VERSION ""

NS_ :

BS_:
BU_: HVC MST DIST TEL MDI STR DRD MPPT MC MEMORATOR OBC
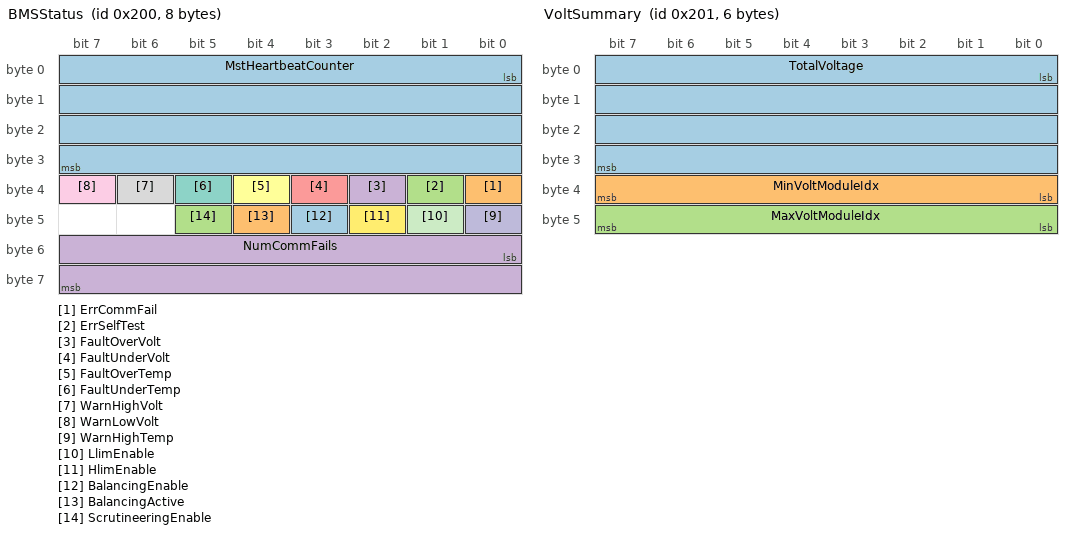
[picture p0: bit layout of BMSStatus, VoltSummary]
BO_ 512 BMSStatus: 8 MST
   SG_ MstHeartbeatCounter : 0|32@1+ (1,0) [0|4.29497e+09] "" HVC
   SG_ ErrCommFail : 32|1@1+ (1,0) [0|1] "" HVC
   SG_ ErrSelfTest : 33|1@1+ (1,0) [0|1] "" HVC
   SG_ FaultOverVolt : 34|1@1+ (1,0) [0|1] "" HVC
   SG_ FaultUnderVolt : 35|1@1+ (1,0) [0|1] "" HVC
   SG_ FaultOverTemp : 36|1@1+ (1,0) [0|1] "" HVC
   SG_ FaultUnderTemp : 37|1@1+ (1,0) [0|1] "" HVC
   SG_ WarnHighVolt : 38|1@1+ (1,0) [0|1] "" HVC
   SG_ WarnLowVolt : 39|1@1+ (1,0) [0|1] "" HVC
   SG_ WarnHighTemp : 40|1@1+ (1,0) [0|1] "" HVC
   SG_ LlimEnable : 41|1@1+ (1,0) [0|1] "" HVC
   SG_ HlimEnable : 42|1@1+ (1,0) [0|1] "" HVC
   SG_ BalancingEnable : 43|1@1+ (1,0) [0|1] "" HVC
   SG_ BalancingActive : 44|1@1+ (1,0) [0|1] "" HVC
   SG_ ScrutineeringEnable : 45|1@1+ (1,0) [0|1] "" HVC
   SG_ NumCommFails : 48|16@1+ (1,0) [0|65535] "" Vector__XXX

BO_ 513 VoltSummary: 6 MST
   SG_ TotalVoltage : 0|32@1+ (1,0) [0|4.29497e+09] "mV" HVC
   SG_ MinVoltModuleIdx : 32|8@1+ (1,0) [0|255] "" Vector__XXX
   SG_ MaxVoltModuleIdx : 40|8@1+ (1,0) [0|255] "" Vector__XXX

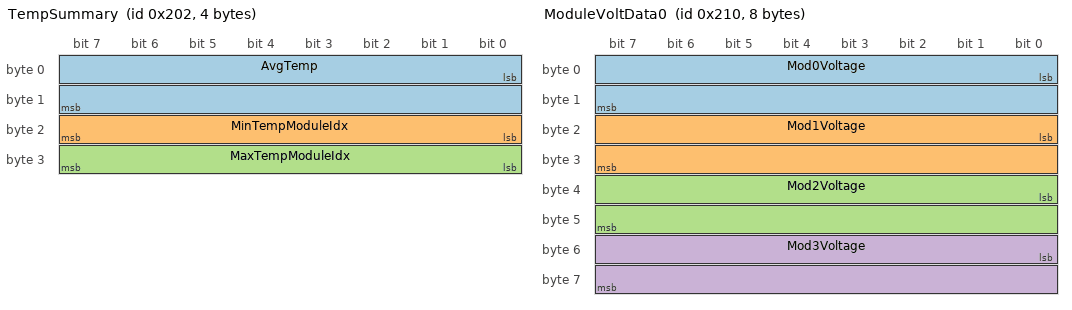
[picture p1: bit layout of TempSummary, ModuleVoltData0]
BO_ 514 TempSummary: 4 MST
   SG_ AvgTemp : 0|16@1- (1,0) [-32768|32767] "degC" Vector__XXX
   SG_ MinTempModuleIdx : 16|8@1+ (1,0) [0|255] "" Vector__XXX
   SG_ MaxTempModuleIdx : 24|8@1+ (1,0) [0|255] "" Vector__XXX

BO_ 515 BalanceData: 4 MST
   SG_ BalanceBitmap : 0|32@1+ (1,0) [0|4.29497e+09] "" Vector__XXX

BO_ 516 MSTCommitHash: 5 MST
   SG_ MSTCommitHash : 7|32@0+ (1,0) [0|4.29497e+09] "" Vector__XXX
   SG_ MSTCommitDirty : 32|1@1+ (1,0) [0|1] "" Vector__XXX

BO_ 528 ModuleVoltData0: 8 MST
   SG_ Mod0Voltage : 0|16@1+ (1,0) [0|65535] "mV" Vector__XXX
   SG_ Mod1Voltage : 16|16@1+ (1,0) [0|65535] "mV" Vector__XXX
   SG_ Mod2Voltage : 32|16@1+ (1,0) [0|65535] "mV" Vector__XXX
   SG_ Mod3Voltage : 48|16@1+ (1,0) [0|65535] "mV" Vector__XXX

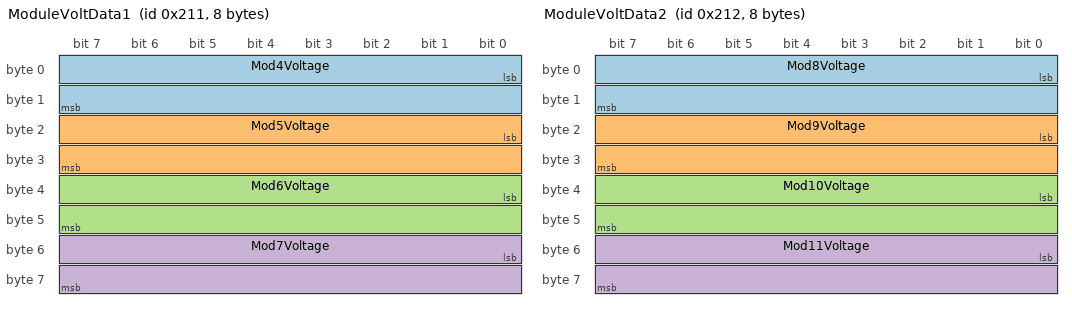
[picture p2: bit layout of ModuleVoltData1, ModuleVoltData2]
BO_ 529 ModuleVoltData1: 8 MST
   SG_ Mod4Voltage : 0|16@1+ (1,0) [0|65535] "mV" Vector__XXX
   SG_ Mod5Voltage : 16|16@1+ (1,0) [0|65535] "mV" Vector__XXX
   SG_ Mod6Voltage : 32|16@1+ (1,0) [0|65535] "mV" Vector__XXX
   SG_ Mod7Voltage : 48|16@1+ (1,0) [0|65535] "mV" Vector__XXX

BO_ 530 ModuleVoltData2: 8 MST
   SG_ Mod8Voltage : 0|16@1+ (1,0) [0|65535] "mV" Vector__XXX
   SG_ Mod9Voltage : 16|16@1+ (1,0) [0|65535] "mV" Vector__XXX
   SG_ Mod10Voltage : 32|16@1+ (1,0) [0|65535] "mV" Vector__XXX
   SG_ Mod11Voltage : 48|16@1+ (1,0) [0|65535] "mV" Vector__XXX

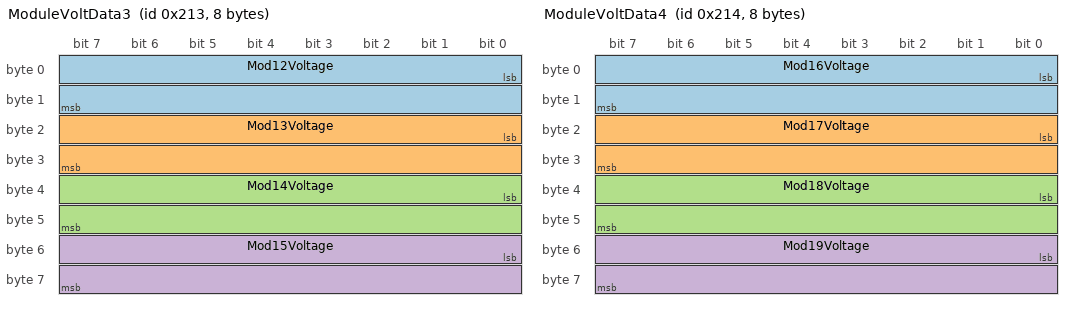
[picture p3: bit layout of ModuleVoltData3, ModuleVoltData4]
BO_ 531 ModuleVoltData3: 8 MST
   SG_ Mod12Voltage : 0|16@1+ (1,0) [0|65535] "mV" Vector__XXX
   SG_ Mod13Voltage : 16|16@1+ (1,0) [0|65535] "mV" Vector__XXX
   SG_ Mod14Voltage : 32|16@1+ (1,0) [0|65535] "mV" Vector__XXX
   SG_ Mod15Voltage : 48|16@1+ (1,0) [0|65535] "mV" Vector__XXX

BO_ 532 ModuleVoltData4: 8 MST
   SG_ Mod16Voltage : 0|16@1+ (1,0) [0|65535] "mV" Vector__XXX
   SG_ Mod17Voltage : 16|16@1+ (1,0) [0|65535] "mV" Vector__XXX
   SG_ Mod18Voltage : 32|16@1+ (1,0) [0|65535] "mV" Vector__XXX
   SG_ Mod19Voltage : 48|16@1+ (1,0) [0|65535] "mV" Vector__XXX

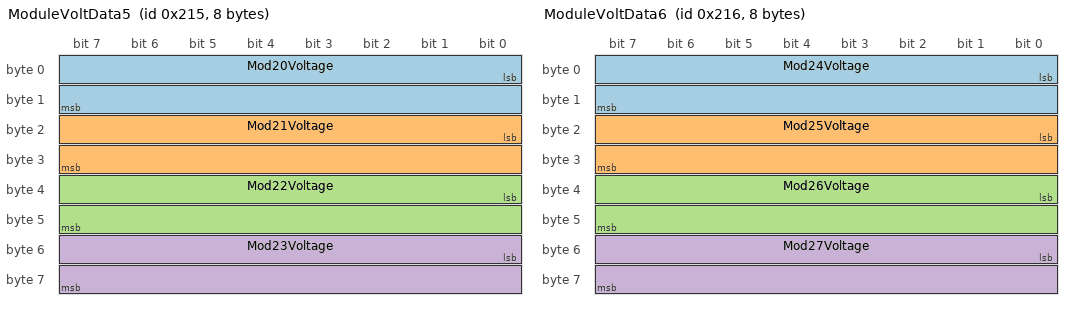
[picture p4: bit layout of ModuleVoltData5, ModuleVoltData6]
BO_ 533 ModuleVoltData5: 8 MST
   SG_ Mod20Voltage : 0|16@1+ (1,0) [0|65535] "mV" Vector__XXX
   SG_ Mod21Voltage : 16|16@1+ (1,0) [0|65535] "mV" Vector__XXX
   SG_ Mod22Voltage : 32|16@1+ (1,0) [0|65535] "mV" Vector__XXX
   SG_ Mod23Voltage : 48|16@1+ (1,0) [0|65535] "mV" Vector__XXX

BO_ 534 ModuleVoltData6: 8 MST
   SG_ Mod24Voltage : 0|16@1+ (1,0) [0|65535] "mV" Vector__XXX
   SG_ Mod25Voltage : 16|16@1+ (1,0) [0|65535] "mV" Vector__XXX
   SG_ Mod26Voltage : 32|16@1+ (1,0) [0|65535] "mV" Vector__XXX
   SG_ Mod27Voltage : 48|16@1+ (1,0) [0|65535] "mV" Vector__XXX

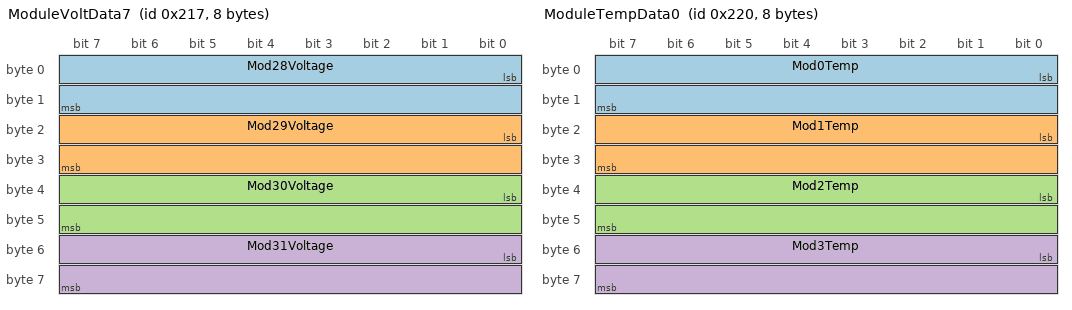
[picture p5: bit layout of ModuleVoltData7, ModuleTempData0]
BO_ 535 ModuleVoltData7: 8 MST
   SG_ Mod28Voltage : 0|16@1+ (1,0) [0|65535] "mV" Vector__XXX
   SG_ Mod29Voltage : 16|16@1+ (1,0) [0|65535] "mV" Vector__XXX
   SG_ Mod30Voltage : 32|16@1+ (1,0) [0|65535] "mV" Vector__XXX
   SG_ Mod31Voltage : 48|16@1+ (1,0) [0|65535] "mV" Vector__XXX

BO_ 544 ModuleTempData0: 8 MST
   SG_ Mod0Temp : 0|16@1- (1,0) [-32768|32767] "degC" Vector__XXX
   SG_ Mod1Temp : 16|16@1- (1,0) [-32768|32767] "degC" Vector__XXX
   SG_ Mod2Temp : 32|16@1- (1,0) [-32768|32767] "degC" Vector__XXX
   SG_ Mod3Temp : 48|16@1- (1,0) [-32768|32767] "degC" Vector__XXX

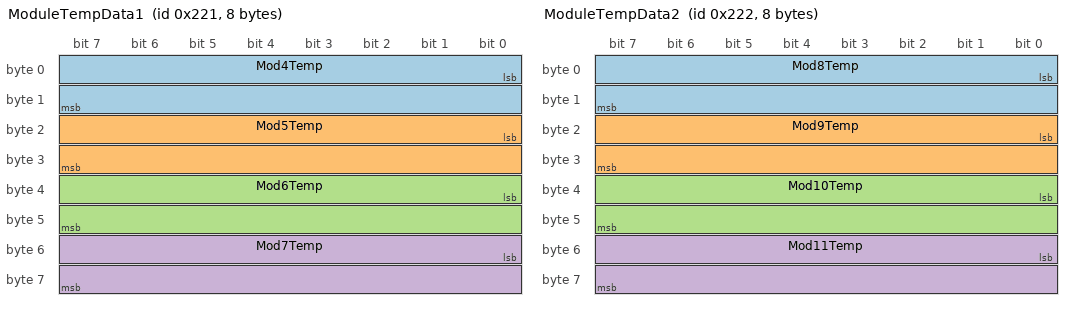
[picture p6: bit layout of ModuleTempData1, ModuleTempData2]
BO_ 545 ModuleTempData1: 8 MST
   SG_ Mod4Temp : 0|16@1- (1,0) [-32768|32767] "degC" Vector__XXX
   SG_ Mod5Temp : 16|16@1- (1,0) [-32768|32767] "degC" Vector__XXX
   SG_ Mod6Temp : 32|16@1- (1,0) [-32768|32767] "degC" Vector__XXX
   SG_ Mod7Temp : 48|16@1- (1,0) [-32768|32767] "degC" Vector__XXX

BO_ 546 ModuleTempData2: 8 MST
   SG_ Mod8Temp : 0|16@1- (1,0) [-32768|32767] "degC" Vector__XXX
   SG_ Mod9Temp : 16|16@1- (1,0) [-32768|32767] "degC" Vector__XXX
   SG_ Mod10Temp : 32|16@1- (1,0) [-32768|32767] "degC" Vector__XXX
   SG_ Mod11Temp : 48|16@1- (1,0) [-32768|32767] "degC" Vector__XXX

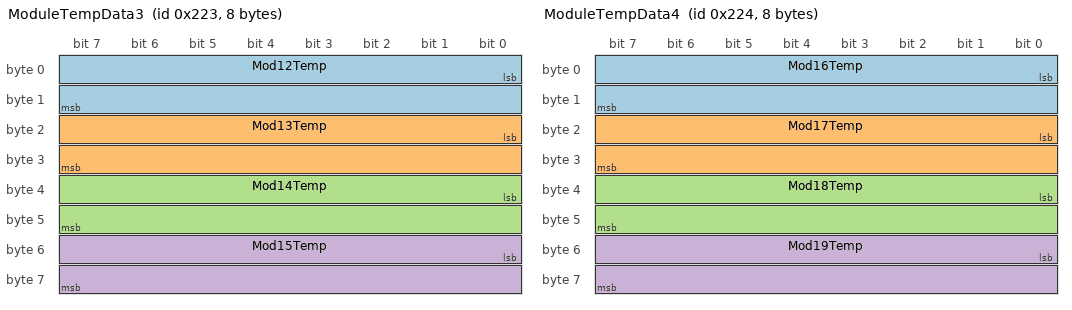
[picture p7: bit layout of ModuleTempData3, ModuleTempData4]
BO_ 547 ModuleTempData3: 8 MST
   SG_ Mod12Temp : 0|16@1- (1,0) [-32768|32767] "degC" Vector__XXX
   SG_ Mod13Temp : 16|16@1- (1,0) [-32768|32767] "degC" Vector__XXX
   SG_ Mod14Temp : 32|16@1- (1,0) [-32768|32767] "degC" Vector__XXX
   SG_ Mod15Temp : 48|16@1- (1,0) [-32768|32767] "degC" Vector__XXX

BO_ 548 ModuleTempData4: 8 MST
   SG_ Mod16Temp : 0|16@1- (1,0) [-32768|32767] "degC" Vector__XXX
   SG_ Mod17Temp : 16|16@1- (1,0) [-32768|32767] "degC" Vector__XXX
   SG_ Mod18Temp : 32|16@1- (1,0) [-32768|32767] "degC" Vector__XXX
   SG_ Mod19Temp : 48|16@1- (1,0) [-32768|32767] "degC" Vector__XXX

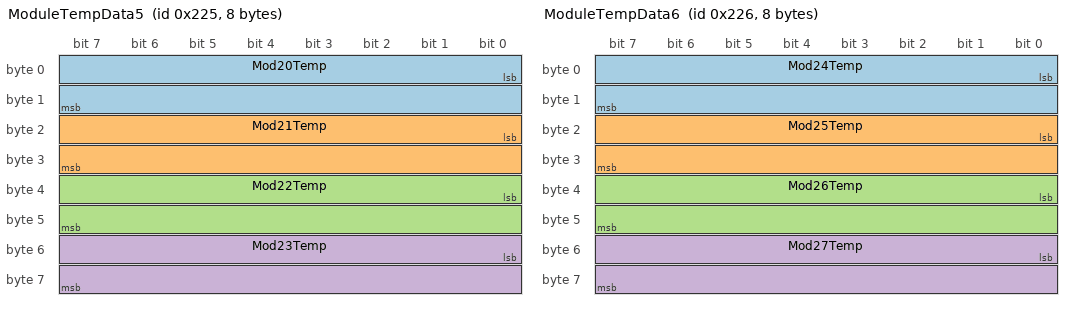
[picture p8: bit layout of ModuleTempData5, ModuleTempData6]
BO_ 549 ModuleTempData5: 8 MST
   SG_ Mod20Temp : 0|16@1- (1,0) [-32768|32767] "degC" Vector__XXX
   SG_ Mod21Temp : 16|16@1- (1,0) [-32768|32767] "degC" Vector__XXX
   SG_ Mod22Temp : 32|16@1- (1,0) [-32768|32767] "degC" Vector__XXX
   SG_ Mod23Temp : 48|16@1- (1,0) [-32768|32767] "degC" Vector__XXX

BO_ 550 ModuleTempData6: 8 MST
   SG_ Mod24Temp : 0|16@1- (1,0) [-32768|32767] "degC" Vector__XXX
   SG_ Mod25Temp : 16|16@1- (1,0) [-32768|32767] "degC" Vector__XXX
   SG_ Mod26Temp : 32|16@1- (1,0) [-32768|32767] "degC" Vector__XXX
   SG_ Mod27Temp : 48|16@1- (1,0) [-32768|32767] "degC" Vector__XXX

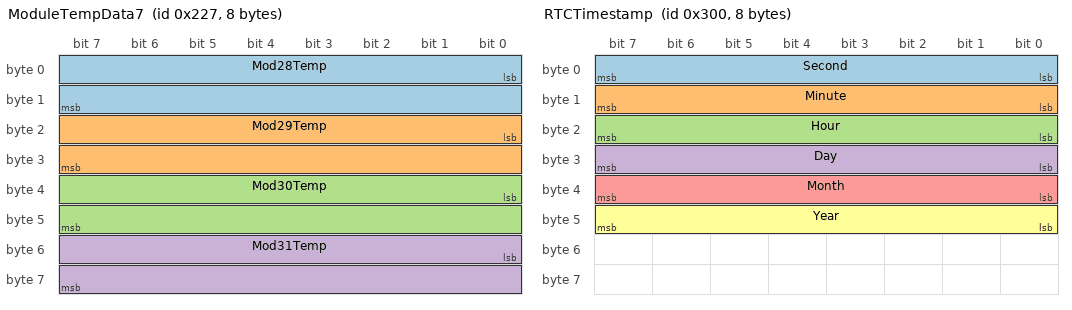
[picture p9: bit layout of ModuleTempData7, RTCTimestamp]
BO_ 551 ModuleTempData7: 8 MST
   SG_ Mod28Temp : 0|16@1- (1,0) [-32768|32767] "degC" Vector__XXX
   SG_ Mod29Temp : 16|16@1- (1,0) [-32768|32767] "degC" Vector__XXX
   SG_ Mod30Temp : 32|16@1- (1,0) [-32768|32767] "degC" Vector__XXX
   SG_ Mod31Temp : 48|16@1- (1,0) [-32768|32767] "degC" Vector__XXX

BO_ 560 ModuleWarnsAndFaults0: 8 MST
   SG_ Mod0WarnHighVolt : 0|1@1+ (1,0) [0|1] "" Vector__XXX
   SG_ Mod0WarnLowVolt : 1|1@1+ (1,0) [0|1] "" Vector__XXX
   SG_ Mod0WarnHighTemp : 2|1@1+ (1,0) [0|1] "" Vector__XXX
   SG_ Mod0FaultOverVolt : 4|1@1+ (1,0) [0|1] "" Vector__XXX
   SG_ Mod0FaultUnderVolt : 5|1@1+ (1,0) [0|1] "" Vector__XXX
   SG_ Mod0FaultOverTemp : 6|1@1+ (1,0) [0|1] "" Vector__XXX
   SG_ Mod0FaultUnderTemp : 7|1@1+ (1,0) [0|1] "" Vector__XXX
   SG_ Mod1WarnHighVolt : 8|1@1+ (1,0) [0|1] "" Vector__XXX
   SG_ Mod1WarnLowVolt : 9|1@1+ (1,0) [0|1] "" Vector__XXX
   SG_ Mod1WarnHighTemp : 10|1@1+ (1,0) [0|1] "" Vector__XXX
   SG_ Mod1FaultOverVolt : 12|1@1+ (1,0) [0|1] "" Vector__XXX
   SG_ Mod1FaultUnderVolt : 13|1@1+ (1,0) [0|1] "" Vector__XXX
   SG_ Mod1FaultOverTemp : 14|1@1+ (1,0) [0|1] "" Vector__XXX
   SG_ Mod1FaultUnderTemp : 15|1@1+ (1,0) [0|1] "" Vector__XXX
   SG_ Mod2WarnHighVolt : 16|1@1+ (1,0) [0|1] "" Vector__XXX
   SG_ Mod2WarnLowVolt : 17|1@1+ (1,0) [0|1] "" Vector__XXX
   SG_ Mod2WarnHighTemp : 18|1@1+ (1,0) [0|1] "" Vector__XXX
   SG_ Mod2FaultOverVolt : 20|1@1+ (1,0) [0|1] "" Vector__XXX
   SG_ Mod2FaultUnderVolt : 21|1@1+ (1,0) [0|1] "" Vector__XXX
   SG_ Mod2FaultOverTemp : 22|1@1+ (1,0) [0|1] "" Vector__XXX
   SG_ Mod2FaultUnderTemp : 23|1@1+ (1,0) [0|1] "" Vector__XXX
   SG_ Mod3WarnHighVolt : 24|1@1+ (1,0) [0|1] "" Vector__XXX
   SG_ Mod3WarnLowVolt : 25|1@1+ (1,0) [0|1] "" Vector__XXX
   SG_ Mod3WarnHighTemp : 26|1@1+ (1,0) [0|1] "" Vector__XXX
   SG_ Mod3FaultOverVolt : 28|1@1+ (1,0) [0|1] "" Vector__XXX
   SG_ Mod3FaultUnderVolt : 29|1@1+ (1,0) [0|1] "" Vector__XXX
   SG_ Mod3FaultOverTemp : 30|1@1+ (1,0) [0|1] "" Vector__XXX
   SG_ Mod3FaultUnderTemp : 31|1@1+ (1,0) [0|1] "" Vector__XXX
   SG_ Mod4WarnHighVolt : 32|1@1+ (1,0) [0|1] "" Vector__XXX
   SG_ Mod4WarnLowVolt : 33|1@1+ (1,0) [0|1] "" Vector__XXX
   SG_ Mod4WarnHighTemp : 34|1@1+ (1,0) [0|1] "" Vector__XXX
   SG_ Mod4FaultOverVolt : 36|1@1+ (1,0) [0|1] "" Vector__XXX
   SG_ Mod4FaultUnderVolt : 37|1@1+ (1,0) [0|1] "" Vector__XXX
   SG_ Mod4FaultOverTemp : 38|1@1+ (1,0) [0|1] "" Vector__XXX
   SG_ Mod4FaultUnderTemp : 39|1@1+ (1,0) [0|1] "" Vector__XXX
   SG_ Mod5WarnHighVolt : 40|1@1+ (1,0) [0|1] "" Vector__XXX
   SG_ Mod5WarnLowVolt : 41|1@1+ (1,0) [0|1] "" Vector__XXX
   SG_ Mod5WarnHighTemp : 42|1@1+ (1,0) [0|1] "" Vector__XXX
   SG_ Mod5FaultOverVolt : 44|1@1+ (1,0) [0|1] "" Vector__XXX
   SG_ Mod5FaultUnderVolt : 45|1@1+ (1,0) [0|1] "" Vector__XXX
   SG_ Mod5FaultOverTemp : 46|1@1+ (1,0) [0|1] "" Vector__XXX
   SG_ Mod5FaultUnderTemp : 47|1@1+ (1,0) [0|1] "" Vector__XXX
   SG_ Mod6WarnHighVolt : 48|1@1+ (1,0) [0|1] "" Vector__XXX
   SG_ Mod6WarnLowVolt : 49|1@1+ (1,0) [0|1] "" Vector__XXX
   SG_ Mod6WarnHighTemp : 50|1@1+ (1,0) [0|1] "" Vector__XXX
   SG_ Mod6FaultOverVolt : 52|1@1+ (1,0) [0|1] "" Vector__XXX
   SG_ Mod6FaultUnderVolt : 53|1@1+ (1,0) [0|1] "" Vector__XXX
   SG_ Mod6FaultOverTemp : 54|1@1+ (1,0) [0|1] "" Vector__XXX
   SG_ Mod6FaultUnderTemp : 55|1@1+ (1,0) [0|1] "" Vector__XXX
   SG_ Mod7WarnHighVolt : 56|1@1+ (1,0) [0|1] "" Vector__XXX
   SG_ Mod7WarnLowVolt : 57|1@1+ (1,0) [0|1] "" Vector__XXX
   SG_ Mod7WarnHighTemp : 58|1@1+ (1,0) [0|1] "" Vector__XXX
   SG_ Mod7FaultOverVolt : 60|1@1+ (1,0) [0|1] "" Vector__XXX
   SG_ Mod7FaultUnderVolt : 61|1@1+ (1,0) [0|1] "" Vector__XXX
   SG_ Mod7FaultOverTemp : 62|1@1+ (1,0) [0|1] "" Vector__XXX
   SG_ Mod7FaultUnderTemp : 63|1@1+ (1,0) [0|1] "" Vector__XXX

BO_ 561 ModuleWarnsAndFaults1: 8 MST
   SG_ Mod8WarnHighVolt : 0|1@1+ (1,0) [0|1] "" Vector__XXX
   SG_ Mod8WarnLowVolt : 1|1@1+ (1,0) [0|1] "" Vector__XXX
   SG_ Mod8WarnHighTemp : 2|1@1+ (1,0) [0|1] "" Vector__XXX
   SG_ Mod8FaultOverVolt : 4|1@1+ (1,0) [0|1] "" Vector__XXX
   SG_ Mod8FaultUnderVolt : 5|1@1+ (1,0) [0|1] "" Vector__XXX
   SG_ Mod8FaultOverTemp : 6|1@1+ (1,0) [0|1] "" Vector__XXX
   SG_ Mod8FaultUnderTemp : 7|1@1+ (1,0) [0|1] "" Vector__XXX
   SG_ Mod9WarnHighVolt : 8|1@1+ (1,0) [0|1] "" Vector__XXX
   SG_ Mod9WarnLowVolt : 9|1@1+ (1,0) [0|1] "" Vector__XXX
   SG_ Mod9WarnHighTemp : 10|1@1+ (1,0) [0|1] "" Vector__XXX
   SG_ Mod9FaultOverVolt : 12|1@1+ (1,0) [0|1] "" Vector__XXX
   SG_ Mod9FaultUnderVolt : 13|1@1+ (1,0) [0|1] "" Vector__XXX
   SG_ Mod9FaultOverTemp : 14|1@1+ (1,0) [0|1] "" Vector__XXX
   SG_ Mod9FaultUnderTemp : 15|1@1+ (1,0) [0|1] "" Vector__XXX
   SG_ Mod10WarnHighVolt : 16|1@1+ (1,0) [0|1] "" Vector__XXX
   SG_ Mod10WarnLowVolt : 17|1@1+ (1,0) [0|1] "" Vector__XXX
   SG_ Mod10WarnHighTemp : 18|1@1+ (1,0) [0|1] "" Vector__XXX
   SG_ Mod10FaultOverVolt : 20|1@1+ (1,0) [0|1] "" Vector__XXX
   SG_ Mod10FaultUnderVolt : 21|1@1+ (1,0) [0|1] "" Vector__XXX
   SG_ Mod10FaultOverTemp : 22|1@1+ (1,0) [0|1] "" Vector__XXX
   SG_ Mod10FaultUnderTemp : 23|1@1+ (1,0) [0|1] "" Vector__XXX
   SG_ Mod11WarnHighVolt : 24|1@1+ (1,0) [0|1] "" Vector__XXX
   SG_ Mod11WarnLowVolt : 25|1@1+ (1,0) [0|1] "" Vector__XXX
   SG_ Mod11WarnHighTemp : 26|1@1+ (1,0) [0|1] "" Vector__XXX
   SG_ Mod11FaultOverVolt : 28|1@1+ (1,0) [0|1] "" Vector__XXX
   SG_ Mod11FaultUnderVolt : 29|1@1+ (1,0) [0|1] "" Vector__XXX
   SG_ Mod11FaultOverTemp : 30|1@1+ (1,0) [0|1] "" Vector__XXX
   SG_ Mod11FaultUnderTemp : 31|1@1+ (1,0) [0|1] "" Vector__XXX
   SG_ Mod12WarnHighVolt : 32|1@1+ (1,0) [0|1] "" Vector__XXX
   SG_ Mod12WarnLowVolt : 33|1@1+ (1,0) [0|1] "" Vector__XXX
   SG_ Mod12WarnHighTemp : 34|1@1+ (1,0) [0|1] "" Vector__XXX
   SG_ Mod12FaultOverVolt : 36|1@1+ (1,0) [0|1] "" Vector__XXX
   SG_ Mod12FaultUnderVolt : 37|1@1+ (1,0) [0|1] "" Vector__XXX
   SG_ Mod12FaultOverTemp : 38|1@1+ (1,0) [0|1] "" Vector__XXX
   SG_ Mod12FaultUnderTemp : 39|1@1+ (1,0) [0|1] "" Vector__XXX
   SG_ Mod13WarnHighVolt : 40|1@1+ (1,0) [0|1] "" Vector__XXX
   SG_ Mod13WarnLowVolt : 41|1@1+ (1,0) [0|1] "" Vector__XXX
   SG_ Mod13WarnHighTemp : 42|1@1+ (1,0) [0|1] "" Vector__XXX
   SG_ Mod13FaultOverVolt : 44|1@1+ (1,0) [0|1] "" Vector__XXX
   SG_ Mod13FaultUnderVolt : 45|1@1+ (1,0) [0|1] "" Vector__XXX
   SG_ Mod13FaultOverTemp : 46|1@1+ (1,0) [0|1] "" Vector__XXX
   SG_ Mod13FaultUnderTemp : 47|1@1+ (1,0) [0|1] "" Vector__XXX
   SG_ Mod14WarnHighVolt : 48|1@1+ (1,0) [0|1] "" Vector__XXX
   SG_ Mod14WarnLowVolt : 49|1@1+ (1,0) [0|1] "" Vector__XXX
   SG_ Mod14WarnHighTemp : 50|1@1+ (1,0) [0|1] "" Vector__XXX
   SG_ Mod14FaultOverVolt : 52|1@1+ (1,0) [0|1] "" Vector__XXX
   SG_ Mod14FaultUnderVolt : 53|1@1+ (1,0) [0|1] "" Vector__XXX
   SG_ Mod14FaultOverTemp : 54|1@1+ (1,0) [0|1] "" Vector__XXX
   SG_ Mod14FaultUnderTemp : 55|1@1+ (1,0) [0|1] "" Vector__XXX
   SG_ Mod15WarnHighVolt : 56|1@1+ (1,0) [0|1] "" Vector__XXX
   SG_ Mod15WarnLowVolt : 57|1@1+ (1,0) [0|1] "" Vector__XXX
   SG_ Mod15WarnHighTemp : 58|1@1+ (1,0) [0|1] "" Vector__XXX
   SG_ Mod15FaultOverVolt : 60|1@1+ (1,0) [0|1] "" Vector__XXX
   SG_ Mod15FaultUnderVolt : 61|1@1+ (1,0) [0|1] "" Vector__XXX
   SG_ Mod15FaultOverTemp : 62|1@1+ (1,0) [0|1] "" Vector__XXX
   SG_ Mod15FaultUnderTemp : 63|1@1+ (1,0) [0|1] "" Vector__XXX

BO_ 562 ModuleWarnsAndFaults2: 8 MST
   SG_ Mod16WarnHighVolt : 0|1@1+ (1,0) [0|1] "" Vector__XXX
   SG_ Mod16WarnLowVolt : 1|1@1+ (1,0) [0|1] "" Vector__XXX
   SG_ Mod16WarnHighTemp : 2|1@1+ (1,0) [0|1] "" Vector__XXX
   SG_ Mod16FaultOverVolt : 4|1@1+ (1,0) [0|1] "" Vector__XXX
   SG_ Mod16FaultUnderVolt : 5|1@1+ (1,0) [0|1] "" Vector__XXX
   SG_ Mod16FaultOverTemp : 6|1@1+ (1,0) [0|1] "" Vector__XXX
   SG_ Mod16FaultUnderTemp : 7|1@1+ (1,0) [0|1] "" Vector__XXX
   SG_ Mod17WarnHighVolt : 8|1@1+ (1,0) [0|1] "" Vector__XXX
   SG_ Mod17WarnLowVolt : 9|1@1+ (1,0) [0|1] "" Vector__XXX
   SG_ Mod17WarnHighTemp : 10|1@1+ (1,0) [0|1] "" Vector__XXX
   SG_ Mod17FaultOverVolt : 12|1@1+ (1,0) [0|1] "" Vector__XXX
   SG_ Mod17FaultUnderVolt : 13|1@1+ (1,0) [0|1] "" Vector__XXX
   SG_ Mod17FaultOverTemp : 14|1@1+ (1,0) [0|1] "" Vector__XXX
   SG_ Mod17FaultUnderTemp : 15|1@1+ (1,0) [0|1] "" Vector__XXX
   SG_ Mod18WarnHighVolt : 16|1@1+ (1,0) [0|1] "" Vector__XXX
   SG_ Mod18WarnLowVolt : 17|1@1+ (1,0) [0|1] "" Vector__XXX
   SG_ Mod18WarnHighTemp : 18|1@1+ (1,0) [0|1] "" Vector__XXX
   SG_ Mod18FaultOverVolt : 20|1@1+ (1,0) [0|1] "" Vector__XXX
   SG_ Mod18FaultUnderVolt : 21|1@1+ (1,0) [0|1] "" Vector__XXX
   SG_ Mod18FaultOverTemp : 22|1@1+ (1,0) [0|1] "" Vector__XXX
   SG_ Mod18FaultUnderTemp : 23|1@1+ (1,0) [0|1] "" Vector__XXX
   SG_ Mod19WarnHighVolt : 24|1@1+ (1,0) [0|1] "" Vector__XXX
   SG_ Mod19WarnLowVolt : 25|1@1+ (1,0) [0|1] "" Vector__XXX
   SG_ Mod19WarnHighTemp : 26|1@1+ (1,0) [0|1] "" Vector__XXX
   SG_ Mod19FaultOverVolt : 28|1@1+ (1,0) [0|1] "" Vector__XXX
   SG_ Mod19FaultUnderVolt : 29|1@1+ (1,0) [0|1] "" Vector__XXX
   SG_ Mod19FaultOverTemp : 30|1@1+ (1,0) [0|1] "" Vector__XXX
   SG_ Mod19FaultUnderTemp : 31|1@1+ (1,0) [0|1] "" Vector__XXX
   SG_ Mod20WarnHighVolt : 32|1@1+ (1,0) [0|1] "" Vector__XXX
   SG_ Mod20WarnLowVolt : 33|1@1+ (1,0) [0|1] "" Vector__XXX
   SG_ Mod20WarnHighTemp : 34|1@1+ (1,0) [0|1] "" Vector__XXX
   SG_ Mod20FaultOverVolt : 36|1@1+ (1,0) [0|1] "" Vector__XXX
   SG_ Mod20FaultUnderVolt : 37|1@1+ (1,0) [0|1] "" Vector__XXX
   SG_ Mod20FaultOverTemp : 38|1@1+ (1,0) [0|1] "" Vector__XXX
   SG_ Mod20FaultUnderTemp : 39|1@1+ (1,0) [0|1] "" Vector__XXX
   SG_ Mod21WarnHighVolt : 40|1@1+ (1,0) [0|1] "" Vector__XXX
   SG_ Mod21WarnLowVolt : 41|1@1+ (1,0) [0|1] "" Vector__XXX
   SG_ Mod21WarnHighTemp : 42|1@1+ (1,0) [0|1] "" Vector__XXX
   SG_ Mod21FaultOverVolt : 44|1@1+ (1,0) [0|1] "" Vector__XXX
   SG_ Mod21FaultUnderVolt : 45|1@1+ (1,0) [0|1] "" Vector__XXX
   SG_ Mod21FaultOverTemp : 46|1@1+ (1,0) [0|1] "" Vector__XXX
   SG_ Mod21FaultUnderTemp : 47|1@1+ (1,0) [0|1] "" Vector__XXX
   SG_ Mod22WarnHighVolt : 48|1@1+ (1,0) [0|1] "" Vector__XXX
   SG_ Mod22WarnLowVolt : 49|1@1+ (1,0) [0|1] "" Vector__XXX
   SG_ Mod22WarnHighTemp : 50|1@1+ (1,0) [0|1] "" Vector__XXX
   SG_ Mod22FaultOverVolt : 52|1@1+ (1,0) [0|1] "" Vector__XXX
   SG_ Mod22FaultUnderVolt : 53|1@1+ (1,0) [0|1] "" Vector__XXX
   SG_ Mod22FaultOverTemp : 54|1@1+ (1,0) [0|1] "" Vector__XXX
   SG_ Mod22FaultUnderTemp : 55|1@1+ (1,0) [0|1] "" Vector__XXX
   SG_ Mod23WarnHighVolt : 56|1@1+ (1,0) [0|1] "" Vector__XXX
   SG_ Mod23WarnLowVolt : 57|1@1+ (1,0) [0|1] "" Vector__XXX
   SG_ Mod23WarnHighTemp : 58|1@1+ (1,0) [0|1] "" Vector__XXX
   SG_ Mod23FaultOverVolt : 60|1@1+ (1,0) [0|1] "" Vector__XXX
   SG_ Mod23FaultUnderVolt : 61|1@1+ (1,0) [0|1] "" Vector__XXX
   SG_ Mod23FaultOverTemp : 62|1@1+ (1,0) [0|1] "" Vector__XXX
   SG_ Mod23FaultUnderTemp : 63|1@1+ (1,0) [0|1] "" Vector__XXX

BO_ 563 ModuleWarnsAndFaults3: 8 MST
   SG_ Mod24WarnHighVolt : 0|1@1+ (1,0) [0|1] "" Vector__XXX
   SG_ Mod24WarnLowVolt : 1|1@1+ (1,0) [0|1] "" Vector__XXX
   SG_ Mod24WarnHighTemp : 2|1@1+ (1,0) [0|1] "" Vector__XXX
   SG_ Mod24FaultOverVolt : 4|1@1+ (1,0) [0|1] "" Vector__XXX
   SG_ Mod24FaultUnderVolt : 5|1@1+ (1,0) [0|1] "" Vector__XXX
   SG_ Mod24FaultOverTemp : 6|1@1+ (1,0) [0|1] "" Vector__XXX
   SG_ Mod24FaultUnderTemp : 7|1@1+ (1,0) [0|1] "" Vector__XXX
   SG_ Mod25WarnHighVolt : 8|1@1+ (1,0) [0|1] "" Vector__XXX
   SG_ Mod25WarnLowVolt : 9|1@1+ (1,0) [0|1] "" Vector__XXX
   SG_ Mod25WarnHighTemp : 10|1@1+ (1,0) [0|1] "" Vector__XXX
   SG_ Mod25FaultOverVolt : 12|1@1+ (1,0) [0|1] "" Vector__XXX
   SG_ Mod25FaultUnderVolt : 13|1@1+ (1,0) [0|1] "" Vector__XXX
   SG_ Mod25FaultOverTemp : 14|1@1+ (1,0) [0|1] "" Vector__XXX
   SG_ Mod25FaultUnderTemp : 15|1@1+ (1,0) [0|1] "" Vector__XXX
   SG_ Mod26WarnHighVolt : 16|1@1+ (1,0) [0|1] "" Vector__XXX
   SG_ Mod26WarnLowVolt : 17|1@1+ (1,0) [0|1] "" Vector__XXX
   SG_ Mod26WarnHighTemp : 18|1@1+ (1,0) [0|1] "" Vector__XXX
   SG_ Mod26FaultOverVolt : 20|1@1+ (1,0) [0|1] "" Vector__XXX
   SG_ Mod26FaultUnderVolt : 21|1@1+ (1,0) [0|1] "" Vector__XXX
   SG_ Mod26FaultOverTemp : 22|1@1+ (1,0) [0|1] "" Vector__XXX
   SG_ Mod26FaultUnderTemp : 23|1@1+ (1,0) [0|1] "" Vector__XXX
   SG_ Mod27WarnHighVolt : 24|1@1+ (1,0) [0|1] "" Vector__XXX
   SG_ Mod27WarnLowVolt : 25|1@1+ (1,0) [0|1] "" Vector__XXX
   SG_ Mod27WarnHighTemp : 26|1@1+ (1,0) [0|1] "" Vector__XXX
   SG_ Mod27FaultOverVolt : 28|1@1+ (1,0) [0|1] "" Vector__XXX
   SG_ Mod27FaultUnderVolt : 29|1@1+ (1,0) [0|1] "" Vector__XXX
   SG_ Mod27FaultOverTemp : 30|1@1+ (1,0) [0|1] "" Vector__XXX
   SG_ Mod27FaultUnderTemp : 31|1@1+ (1,0) [0|1] "" Vector__XXX
   SG_ Mod28WarnHighVolt : 32|1@1+ (1,0) [0|1] "" Vector__XXX
   SG_ Mod28WarnLowVolt : 33|1@1+ (1,0) [0|1] "" Vector__XXX
   SG_ Mod28WarnHighTemp : 34|1@1+ (1,0) [0|1] "" Vector__XXX
   SG_ Mod28FaultOverVolt : 36|1@1+ (1,0) [0|1] "" Vector__XXX
   SG_ Mod28FaultUnderVolt : 37|1@1+ (1,0) [0|1] "" Vector__XXX
   SG_ Mod28FaultOverTemp : 38|1@1+ (1,0) [0|1] "" Vector__XXX
   SG_ Mod28FaultUnderTemp : 39|1@1+ (1,0) [0|1] "" Vector__XXX
   SG_ Mod29WarnHighVolt : 40|1@1+ (1,0) [0|1] "" Vector__XXX
   SG_ Mod29WarnLowVolt : 41|1@1+ (1,0) [0|1] "" Vector__XXX
   SG_ Mod29WarnHighTemp : 42|1@1+ (1,0) [0|1] "" Vector__XXX
   SG_ Mod29FaultOverVolt : 44|1@1+ (1,0) [0|1] "" Vector__XXX
   SG_ Mod29FaultUnderVolt : 45|1@1+ (1,0) [0|1] "" Vector__XXX
   SG_ Mod29FaultOverTemp : 46|1@1+ (1,0) [0|1] "" Vector__XXX
   SG_ Mod29FaultUnderTemp : 47|1@1+ (1,0) [0|1] "" Vector__XXX
   SG_ Mod30WarnHighVolt : 48|1@1+ (1,0) [0|1] "" Vector__XXX
   SG_ Mod30WarnLowVolt : 49|1@1+ (1,0) [0|1] "" Vector__XXX
   SG_ Mod30WarnHighTemp : 50|1@1+ (1,0) [0|1] "" Vector__XXX
   SG_ Mod30FaultOverVolt : 52|1@1+ (1,0) [0|1] "" Vector__XXX
   SG_ Mod30FaultUnderVolt : 53|1@1+ (1,0) [0|1] "" Vector__XXX
   SG_ Mod30FaultOverTemp : 54|1@1+ (1,0) [0|1] "" Vector__XXX
   SG_ Mod30FaultUnderTemp : 55|1@1+ (1,0) [0|1] "" Vector__XXX
   SG_ Mod31WarnHighVolt : 56|1@1+ (1,0) [0|1] "" Vector__XXX
   SG_ Mod31WarnLowVolt : 57|1@1+ (1,0) [0|1] "" Vector__XXX
   SG_ Mod31WarnHighTemp : 58|1@1+ (1,0) [0|1] "" Vector__XXX
   SG_ Mod31FaultOverVolt : 60|1@1+ (1,0) [0|1] "" Vector__XXX
   SG_ Mod31FaultUnderVolt : 61|1@1+ (1,0) [0|1] "" Vector__XXX
   SG_ Mod31FaultOverTemp : 62|1@1+ (1,0) [0|1] "" Vector__XXX
   SG_ Mod31FaultUnderTemp : 63|1@1+ (1,0) [0|1] "" Vector__XXX

BO_ 768 RTCTimestamp: 8 MEMORATOR
   SG_ Second : 0|8@1+ (1,0) [0|59] "s" TEL
   SG_ Minute : 8|8@1+ (1,0) [0|59] "min" TEL
   SG_ Hour : 16|8@1+ (1,0) [0|23] "h" TEL
   SG_ Day : 24|8@1+ (1,0) [0.99999|31] "" TEL
   SG_ Month : 32|8@1+ (1,0) [0.99999|12] "" TEL
   SG_ Year : 40|8@1+ (1,0) [0|255] "" TEL

BO_ 800 HVCShuntCurrent: 4 HVC
   SG_ PackCurrent : 7|32@0- (1,0) [-2.14749e+09|2.14749e+09] "mA" Vector__XXX

BO_ 801 HvcFault: 3 HVC
   SG_ DcdcFault : 0|1@1+ (1,0) [0|1] "" DIST
   SG_ DistFaultFlag : 1|1@1+ (1,0) [0|1] "" DIST
   SG_ UndercurrentFault : 2|1@1+ (1,0) [0|1] "" DIST
   SG_ OvercurrentFault : 3|1@1+ (1,0) [0|1] "" DIST
   SG_ MstUnhealthyFault : 4|1@1+ (1,0) [0|1] "" DIST
   SG_ MasterboardFault : 5|1@1+ (1,0) [0|1] "" DIST
   SG_ ImdFault : 6|1@1+ (1,0) [0|1] "" DIST
   SG_ EstopFault : 7|1@1+ (1,0) [0|1] "" DIST
   SG_ OpenDischargeRelayTimeout : 8|1@1+ (1,0) [0|1] "" DIST
   SG_ HvConnectTimeout : 9|1@1+ (1,0) [0|1] "" DIST
   SG_ MstStatusCheckTimeout : 10|1@1+ (1,0) [0|1] "" DIST
   SG_ MstHandshakeTimeout : 11|1@1+ (1,0) [0|1] "" DIST
   SG_ TelStartupTimeout : 12|1@1+ (1,0) [0|1] "" DIST
   SG_ DcdcThermistorFault : 13|1@1+ (1,0) [0|1] "" DIST
   SG_ HVCWatchdogReset : 14|1@1+ (1,0) [0|1] "" DIST
   SG_ SuppFault : 15|1@1+ (1,0) [0|1] "" DIST
   SG_ DistHeartbeatTimeout : 18|1@1+ (1,0) [0|1] "" DIST
   SG_ MstHeartbeatTimeout : 19|1@1+ (1,0) [0|1] "" DIST
   SG_ TelHeartbeatTimeout : 20|1@1+ (1,0) [0|1] "" DIST
   SG_ LvPowerupTimeout : 21|1@1+ (1,0) [0|1] "" DIST
   SG_ MpptPrechargeTimeout : 22|1@1+ (1,0) [0|1] "" DIST
   SG_ MotorPrechargeTimeout : 23|1@1+ (1,0) [0|1] "" DIST

BO_ 802 HVCHeartbeat: 4 HVC
   SG_ HVCTimeSinceBootUp : 7|32@0+ (1,0) [0|4.29497e+09] "" Vector__XXX

BO_ 803 HVCLvPowerupSent: 1 HVC
   SG_ HVCLvPowerupSent : 0|8@1+ (1,0) [0|1] "" DIST

BO_ 804 HvcStatus: 1 HVC
   SG_ HVCState : 0|8@1+ (1,0) [0|14] "" Vector__XXX

BO_ 805 HvcLvCurrent: 2 HVC
   SG_ LvCurrent : 7|16@0- (1,0) [-32768|32767] "mA" Vector__XXX

BO_ 806 HvcDcdcTemp: 4 HVC
   SG_ DcdcTemperature : 7|32@0- (0.001,0) [-2.14749e+06|2.14749e+06] "degC" Vector__XXX

BO_ 807 HvcSuppVoltage: 4 HVC
   SG_ SuppVoltage : 7|32@0+ (1,0) [0|4.29497e+09] "mV" Vector__XXX

BO_ 808 HvcMcPrecharge: 4 HVC
   SG_ MotorPrechargeVoltage : 7|32@0- (1,0) [-2.14749e+09|2.14749e+09] "mV" Vector__XXX

BO_ 809 HvcMpptPrecharge: 4 HVC
   SG_ MpptPrechargeVoltage : 7|32@0- (1,0) [-2.14749e+09|2.14749e+09] "mV" Vector__XXX

BO_ 810 HVCCommitHash: 5 HVC
   SG_ HVCCommitHash : 7|32@0+ (1,0) [0|4.29497e+09] "" Vector__XXX
   SG_ HVCCommitDirty : 32|1@1+ (1,0) [0|1] "" Vector__XXX

BO_ 928 DISTHeartBeat: 4 DIST
   SG_ DISTHeartbeatCounter : 7|32@0+ (1,0) [0|4.29497e+09] "" HVC

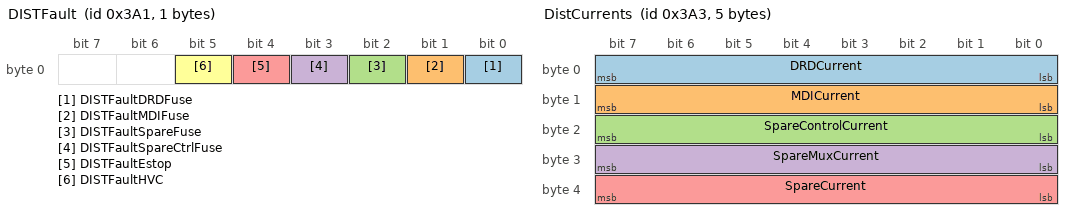
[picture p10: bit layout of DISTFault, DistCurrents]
BO_ 929 DISTFault: 1 DIST
   SG_ DISTFaultDRDFuse : 0|1@1+ (1,0) [0|1] "" HVC
   SG_ DISTFaultMDIFuse : 1|1@1+ (1,0) [0|1] "" HVC
   SG_ DISTFaultSpareFuse : 2|1@1+ (1,0) [0|1] "" HVC
   SG_ DISTFaultSpareCtrlFuse : 3|1@1+ (1,0) [0|1] "" HVC
   SG_ DISTFaultEstop : 4|1@1+ (1,0) [0|1] "" HVC
   SG_ DISTFaultHVC : 5|1@1+ (1,0) [0|1] "" HVC

BO_ 930 DISTLVOn: 1 DIST
   SG_ DISTLVOn : 0|8@1+ (1,0) [0|1] "" HVC

BO_ 931 DistCurrents: 5 DIST
   SG_ DRDCurrent : 0|8@1+ (5,0) [0|1275] "mA" Vector__XXX
   SG_ MDICurrent : 8|8@1+ (5,0) [0|1275] "mA" Vector__XXX
   SG_ SpareControlCurrent : 16|8@1+ (5,0) [0|1275] "mA" Vector__XXX
   SG_ SpareMuxCurrent : 24|8@1+ (5,0) [0|1275] "mA" Vector__XXX
   SG_ SpareCurrent : 32|8@1+ (5,0) [0|1275] "mA" Vector__XXX

BO_ 932 DISTBranchId: 1 DIST
   SG_ DISTBranchId : 0|8@1+ (1,0) [0|255] "" Vector__XXX

BO_ 933 DISTCommitHash: 5 DIST
   SG_ DISTCommitHash : 7|32@0+ (1,0) [0|4.29497e+09] "" Vector__XXX
   SG_ DISTCommitDirty : 32|1@1+ (1,0) [0|1] "" Vector__XXX

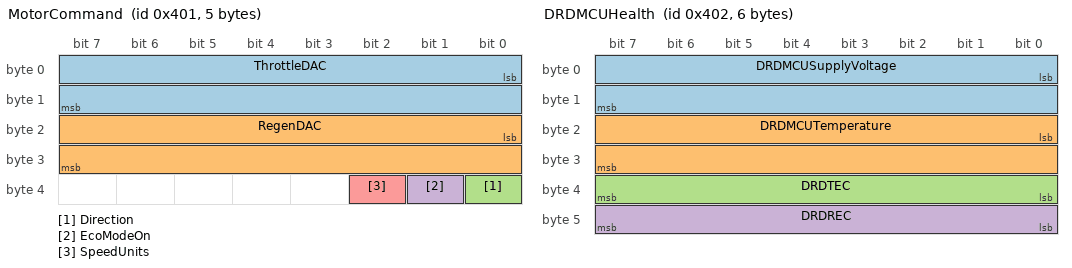
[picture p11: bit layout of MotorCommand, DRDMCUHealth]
BO_ 1025 MotorCommand: 5 DRD
   SG_ ThrottleDAC : 0|16@1+ (1,0) [0|1023] "" MDI
   SG_ RegenDAC : 16|16@1+ (1,0) [0|1023] "" MDI
   SG_ Direction : 32|1@1+ (1,0) [0|1] "" MDI
   SG_ EcoModeOn : 33|1@1+ (1,0) [0|1] "" MDI
   SG_ SpeedUnits : 34|1@1+ (1,0) [0|1] "" STR

BO_ 1026 DRDMCUHealth: 6 DRD
   SG_ DRDMCUSupplyVoltage : 0|16@1+ (1,0) [0|4000] "mV" Vector__XXX
   SG_ DRDMCUTemperature : 16|16@1- (1,0) [-40|125] "degC" Vector__XXX
   SG_ DRDTEC : 32|8@1+ (1,0) [0|255] "" Vector__XXX
   SG_ DRDREC : 40|8@1+ (1,0) [0|255] "" Vector__XXX

BO_ 1027 DRDDiagnostics: 8 DRD
   SG_ RawADC1 : 0|16@1+ (1,0) [0|65535] "" Vector__XXX
   SG_ RawADC2 : 16|16@1+ (1,0) [0|65535] "" Vector__XXX
   SG_ BrakePressed : 32|1@1+ (1,0) [0|1] "" Vector__XXX
   SG_ RegenEnabled : 33|1@1+ (1,0) [0|1] "" Vector__XXX
   SG_ ADCOutOfRange : 34|1@1+ (1,0) [0|1] "" Vector__XXX
   SG_ ADCMismatch : 35|1@1+ (1,0) [0|1] "" Vector__XXX
   SG_ DRDWatchdogReset : 36|1@1+ (1,0) [0|1] "" Vector__XXX
   SG_ MotorCommFault : 37|1@1+ (1,0) [0|1] "" Vector__XXX
   SG_ DRDMCUOverTemp : 38|1@1+ (1,0) [0|1] "" Vector__XXX
   SG_ DRDMCUUnderVoltage : 39|1@1+ (1,0) [0|1] "" Vector__XXX
   SG_ DriveState : 40|8@1+ (1,0) [0|255] "" Vector__XXX
   SG_ SpeedTimeout : 48|1@1+ (1,0) [0|1] "" Vector__XXX
   SG_ DriveStateTimeout : 49|1@1+ (1,0) [0|1] "" Vector__XXX
   SG_ SOCTimeout : 50|1@1+ (1,0) [0|1] "" Vector__XXX
   SG_ VoltageTimeout : 51|1@1+ (1,0) [0|1] "" Vector__XXX
   SG_ CurrentTimeout : 52|1@1+ (1,0) [0|1] "" Vector__XXX
   SG_ SOC : 56|8@1+ (1,0) [0|104] "%" Vector__XXX
   SG_ AccelTimeout : 53|1@1+ (1,0) [0|1] "" Vector__XXX

BO_ 1028 DRDTimeSinceBootup: 4 DRD
   SG_ DRDTimeSinceBootUp : 0|32@1+ (1,0) [0|4.29497e+09] "" Vector__XXX

BO_ 1029 DRDCommitHash: 5 DRD
   SG_ DRDCommitHash : 7|32@0+ (1,0) [0|4.29497e+09] "" Vector__XXX
   SG_ DRDCommitDirty : 32|1@1+ (1,0) [0|1] "" Vector__XXX

BO_ 1280 MDITimeSinceBootup: 4 MDI
   SG_ MDITimeSinceBootUp : 0|32@1+ (1,0) [0|4.29497e+09] "s" Vector__XXX

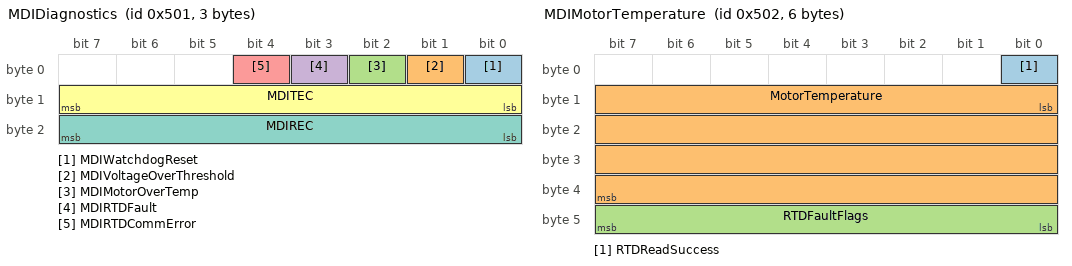
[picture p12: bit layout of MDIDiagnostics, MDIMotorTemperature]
BO_ 1281 MDIDiagnostics: 3 MDI
   SG_ MDIWatchdogReset : 0|1@1+ (1,0) [0|1] "" Vector__XXX
   SG_ MDIVoltageOverThreshold : 1|1@1+ (1,0) [0|1] "" Vector__XXX
   SG_ MDIMotorOverTemp : 2|1@1+ (1,0) [0|1] "" Vector__XXX
   SG_ MDIRTDFault : 3|1@1+ (1,0) [0|1] "" Vector__XXX
   SG_ MDIRTDCommError : 4|1@1+ (1,0) [0|1] "" Vector__XXX
   SG_ MDITEC : 8|8@1+ (1,0) [0|255] "" Vector__XXX
   SG_ MDIREC : 16|8@1+ (1,0) [0|255] "" Vector__XXX

BO_ 1282 MDIMotorTemperature: 6 MDI
   SG_ RTDReadSuccess : 0|1@1+ (1,0) [0|1] "" Vector__XXX
   SG_ MotorTemperature : 8|32@1- (1,0) [-100|300] "degC" Vector__XXX
   SG_ RTDFaultFlags : 40|8@1+ (1,0) [0|255] "" Vector__XXX

BO_ 1284 MDICommitHash: 5 MDI
   SG_ MDICommitHash : 7|32@0+ (1,0) [0|4.29497e+09] "" Vector__XXX
   SG_ MDICommitDirty : 32|1@1+ (1,0) [0|1] "" Vector__XXX

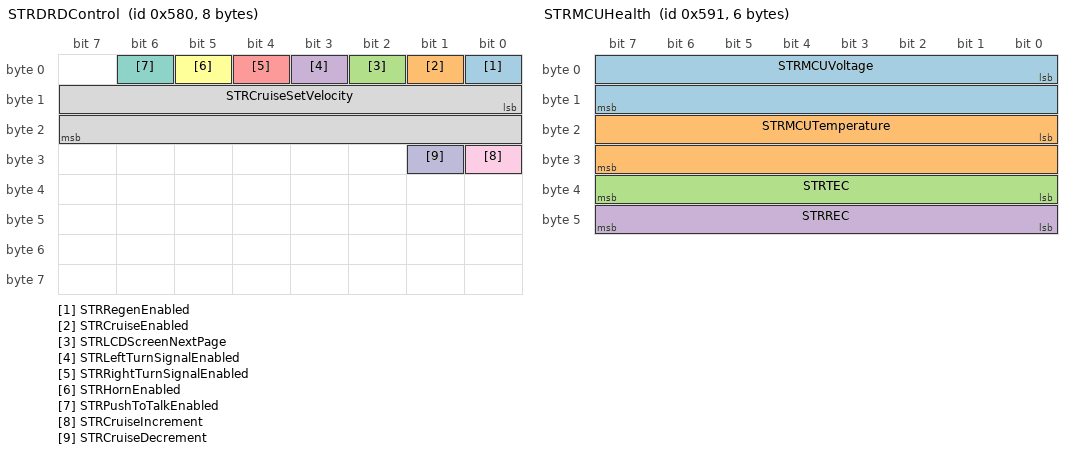
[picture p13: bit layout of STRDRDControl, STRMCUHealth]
BO_ 1408 STRDRDControl: 8 STR
   SG_ STRRegenEnabled : 0|1@1+ (1,0) [0|1] "" Vector__XXX
   SG_ STRCruiseEnabled : 1|1@1+ (1,0) [0|1] "" Vector__XXX
   SG_ STRLCDScreenNextPage : 2|1@1+ (1,0) [0|1] "" Vector__XXX
   SG_ STRLeftTurnSignalEnabled : 3|1@1+ (1,0) [0|1] "" Vector__XXX
   SG_ STRRightTurnSignalEnabled : 4|1@1+ (1,0) [0|1] "" Vector__XXX
   SG_ STRHornEnabled : 5|1@1+ (1,0) [0|1] "" Vector__XXX
   SG_ STRPushToTalkEnabled : 6|1@1+ (1,0) [0|1] "" Vector__XXX
   SG_ STRCruiseSetVelocity : 8|16@1+ (1,0) [0|65535] "km/h" Vector__XXX
   SG_ STRCruiseIncrement : 24|1@1+ (1,0) [0|1] "" Vector__XXX
   SG_ STRCruiseDecrement : 25|1@1+ (1,0) [0|1] "" Vector__XXX

BO_ 1409 STRTimeSinceBootup: 4 STR
   SG_ STRTimeSinceBootUp : 0|32@1+ (1,0) [0|4.29497e+09] "s" Vector__XXX

BO_ 1410 STRDiagnostics: 1 STR
   SG_ STRWatchdogReset : 0|1@1+ (1,0) [0|1] "" Vector__XXX

BO_ 1411 STRCommitHash: 5 STR
   SG_ STRCommitHash : 7|32@0+ (1,0) [0|4.29497e+09] "" Vector__XXX
   SG_ STRCommitDirty : 32|1@1+ (1,0) [0|1] "" Vector__XXX

BO_ 1425 STRMCUHealth: 6 STR
   SG_ STRMCUVoltage : 0|16@1+ (1,0) [0|65535] "mV" Vector__XXX
   SG_ STRMCUTemperature : 16|16@1- (1,0) [-40|125] "degC" Vector__XXX
   SG_ STRTEC : 32|8@1+ (1,0) [0|255] "" Vector__XXX
   SG_ STRREC : 40|8@1+ (1,0) [0|255] "" Vector__XXX

BO_ 1426 STRFlags: 1 STR
   SG_ STRMCUUnderVoltage : 0|1@1+ (1,0) [0|1] "" Vector__XXX
   SG_ STRMCUOverTemp : 1|1@1+ (1,0) [0|1] "" Vector__XXX

BO_ 1696 MPPTInputMeasurementsA: 8 MPPT
   SG_ InputVoltageA : 0|32@1- (1,0) [-3.4e+38|3.4e+38] "V" Vector__XXX
   SG_ InputCurrentA : 32|32@1- (1,0) [-3.4e+38|3.4e+38] "A" Vector__XXX

BO_ 1697 MPPTOutputMeasurementsA: 8 MPPT
   SG_ OutputVoltageA : 0|32@1- (1,0) [-3.4e+38|3.4e+38] "V" Vector__XXX
   SG_ OutputCurrentA : 32|32@1- (1,0) [-3.4e+38|3.4e+38] "A" Vector__XXX

BO_ 1698 MPPTTemperatureA: 8 MPPT
   SG_ MosfetTemperatureA : 0|32@1- (1,0) [-40|150] "degC" Vector__XXX
   SG_ ControllerTemperatureA : 32|32@1- (1,0) [-40|150] "degC" DRD

BO_ 1699 MPPTAuxiliaryPowerSupplyA: 8 MPPT
   SG_ Aux12VA : 0|32@1- (1,0) [0|20] "V" Vector__XXX
   SG_ Aux3VA : 32|32@1- (1,0) [0|5] "V" Vector__XXX

BO_ 1700 MPPTLimitsA: 8 MPPT
   SG_ MaxOutputVoltageLimitA : 0|32@1- (1,0) [-3.4e+38|3.4e+38] "V" Vector__XXX
   SG_ MaxInputCurrentLimitA : 32|32@1- (1,0) [-3.4e+38|3.4e+38] "A" Vector__XXX

BO_ 1701 MPPTStatusA: 8 MPPT
   SG_ CANRXErrorCounterA : 0|8@1+ (1,0) [0|255] "" Vector__XXX
   SG_ CANTXErrorCounterA : 8|8@1+ (1,0) [0|255] "" Vector__XXX
   SG_ CANTXOverflowCounterA : 16|8@1+ (1,0) [0|255] "" Vector__XXX
   SG_ HWOvervoltageA : 24|1@1+ (1,0) [0|1] "" Vector__XXX
   SG_ HWOvercurrentA : 25|1@1+ (1,0) [0|1] "" Vector__XXX
   SG_ Reserved1A : 26|1@1+ (1,0) [0|1] "" Vector__XXX
   SG_ Undervoltage12VA : 27|1@1+ (1,0) [0|1] "" Vector__XXX
   SG_ BatteryFullA : 28|1@1+ (1,0) [0|1] "" Vector__XXX
   SG_ BatteryLowA : 29|1@1+ (1,0) [0|1] "" Vector__XXX
   SG_ MosfetOverheatA : 30|1@1+ (1,0) [0|1] "" Vector__XXX
   SG_ LowArrayPowerA : 31|1@1+ (1,0) [0|1] "" Vector__XXX
   SG_ GlobalMPPTA : 32|1@1+ (1,0) [0|1] "" Vector__XXX
   SG_ LocalMPPTA : 33|1@1+ (1,0) [0|1] "" Vector__XXX
   SG_ DutyCycleMaxA : 34|1@1+ (1,0) [0|1] "" Vector__XXX
   SG_ DutyCycleMinA : 35|1@1+ (1,0) [0|1] "" Vector__XXX
   SG_ MosfetTempFaultA : 36|1@1+ (1,0) [0|1] "" Vector__XXX
   SG_ OutputVoltageMaxA : 37|1@1+ (1,0) [0|1] "" Vector__XXX
   SG_ InputCurrentMaxA : 38|1@1+ (1,0) [0|1] "" Vector__XXX
   SG_ InputCurrentMinA : 39|1@1+ (1,0) [0|1] "" Vector__XXX
   SG_ ModeA : 40|8@1+ (1,0) [0|1] "" Vector__XXX
   SG_ Reserved2A : 48|8@1+ (1,0) [0|255] "" Vector__XXX
   SG_ TestCounterA : 56|8@1+ (1,0) [0|255] "" Vector__XXX

BO_ 1702 MPPTPowerConnectorA: 8 MPPT
   SG_ OutputVoltageBattSideA : 0|32@1- (1,0) [-3.4e+38|3.4e+38] "V" Vector__XXX
   SG_ ConnectorTemperatureA : 32|32@1- (1,0) [-40|150] "degC" Vector__XXX

BO_ 1704 MPPTModeCommandA: 1 Vector__XXX
   SG_ ModeCmdA : 0|8@1+ (1,0) [0|1] "" Vector__XXX

BO_ 1706 MPPTMaxOutputVoltageCommandA: 4 Vector__XXX
   SG_ MaxOutputVoltageCmdA : 0|32@1- (1,0) [-3.4e+38|3.4e+38] "V" Vector__XXX

BO_ 1707 MPPTMaxOutputCurrentCommandA: 4 Vector__XXX
   SG_ MaxOutputCurrentCmdA : 0|32@1- (1,0) [-3.4e+38|3.4e+38] "A" Vector__XXX

BO_ 1712 MPPTInputMeasurementsB: 8 MPPT
   SG_ InputVoltageB : 0|32@1- (1,0) [-3.4e+38|3.4e+38] "V" Vector__XXX
   SG_ InputCurrentB : 32|32@1- (1,0) [-3.4e+38|3.4e+38] "A" Vector__XXX

BO_ 1713 MPPTOutputMeasurementsB: 8 MPPT
   SG_ OutputVoltageB : 0|32@1- (1,0) [-3.4e+38|3.4e+38] "V" Vector__XXX
   SG_ OutputCurrentB : 32|32@1- (1,0) [-3.4e+38|3.4e+38] "A" Vector__XXX

BO_ 1714 MPPTTemperatureB: 8 MPPT
   SG_ MosfetTemperatureB : 0|32@1- (1,0) [-40|150] "degC" Vector__XXX
   SG_ ControllerTemperatureB : 32|32@1- (1,0) [-40|150] "degC" DRD

BO_ 1715 MPPTAuxiliaryPowerSupplyB: 8 MPPT
   SG_ Aux12VB : 0|32@1- (1,0) [0|20] "V" Vector__XXX
   SG_ Aux3VB : 32|32@1- (1,0) [0|5] "V" Vector__XXX

BO_ 1716 MPPTLimitsB: 8 MPPT
   SG_ MaxOutputVoltageLimitB : 0|32@1- (1,0) [-3.4e+38|3.4e+38] "V" Vector__XXX
   SG_ MaxInputCurrentLimitB : 32|32@1- (1,0) [-3.4e+38|3.4e+38] "A" Vector__XXX

BO_ 1717 MPPTStatusB: 8 MPPT
   SG_ CANRXErrorCounterB : 0|8@1+ (1,0) [0|255] "" Vector__XXX
   SG_ CANTXErrorCounterB : 8|8@1+ (1,0) [0|255] "" Vector__XXX
   SG_ CANTXOverflowCounterB : 16|8@1+ (1,0) [0|255] "" Vector__XXX
   SG_ HWOvervoltageB : 24|1@1+ (1,0) [0|1] "" Vector__XXX
   SG_ HWOvercurrentB : 25|1@1+ (1,0) [0|1] "" Vector__XXX
   SG_ Reserved1B : 26|1@1+ (1,0) [0|1] "" Vector__XXX
   SG_ Undervoltage12VB : 27|1@1+ (1,0) [0|1] "" Vector__XXX
   SG_ BatteryFullB : 28|1@1+ (1,0) [0|1] "" Vector__XXX
   SG_ BatteryLowB : 29|1@1+ (1,0) [0|1] "" Vector__XXX
   SG_ MosfetOverheatB : 30|1@1+ (1,0) [0|1] "" Vector__XXX
   SG_ LowArrayPowerB : 31|1@1+ (1,0) [0|1] "" Vector__XXX
   SG_ GlobalMPPTB : 32|1@1+ (1,0) [0|1] "" Vector__XXX
   SG_ LocalMPPTB : 33|1@1+ (1,0) [0|1] "" Vector__XXX
   SG_ DutyCycleMaxB : 34|1@1+ (1,0) [0|1] "" Vector__XXX
   SG_ DutyCycleMinB : 35|1@1+ (1,0) [0|1] "" Vector__XXX
   SG_ MosfetTempFaultB : 36|1@1+ (1,0) [0|1] "" Vector__XXX
   SG_ OutputVoltageMaxB : 37|1@1+ (1,0) [0|1] "" Vector__XXX
   SG_ InputCurrentMaxB : 38|1@1+ (1,0) [0|1] "" Vector__XXX
   SG_ InputCurrentMinB : 39|1@1+ (1,0) [0|1] "" Vector__XXX
   SG_ ModeB : 40|8@1+ (1,0) [0|1] "" Vector__XXX
   SG_ Reserved2B : 48|8@1+ (1,0) [0|255] "" Vector__XXX
   SG_ TestCounterB : 56|8@1+ (1,0) [0|255] "" Vector__XXX

BO_ 1718 MPPTPowerConnectorB: 8 MPPT
   SG_ OutputVoltageBattSideB : 0|32@1- (1,0) [-3.4e+38|3.4e+38] "V" Vector__XXX
   SG_ ConnectorTemperatureB : 32|32@1- (1,0) [-40|150] "degC" Vector__XXX

BO_ 1720 MPPTModeCommandB: 1 Vector__XXX
   SG_ ModeCmdB : 0|8@1+ (1,0) [0|1] "" Vector__XXX

BO_ 1722 MPPTMaxOutputVoltageCommandB: 4 Vector__XXX
   SG_ MaxOutputVoltageCmdB : 0|32@1- (1,0) [-3.4e+38|3.4e+38] "V" Vector__XXX

BO_ 1723 MPPTMaxOutputCurrentCommandB: 4 Vector__XXX
   SG_ MaxOutputCurrentCmdB : 0|32@1- (1,0) [-3.4e+38|3.4e+38] "A" Vector__XXX

BO_ 1728 MPPTInputMeasurementsC: 8 MPPT
   SG_ InputVoltageC : 0|32@1- (1,0) [-3.4e+38|3.4e+38] "V" Vector__XXX
   SG_ InputCurrentC : 32|32@1- (1,0) [-3.4e+38|3.4e+38] "A" Vector__XXX

BO_ 1729 MPPTOutputMeasurementsC: 8 MPPT
   SG_ OutputVoltageC : 0|32@1- (1,0) [-3.4e+38|3.4e+38] "V" Vector__XXX
   SG_ OutputCurrentC : 32|32@1- (1,0) [-3.4e+38|3.4e+38] "A" Vector__XXX

BO_ 1730 MPPTTemperatureC: 8 MPPT
   SG_ MosfetTemperatureC : 0|32@1- (1,0) [-40|150] "degC" Vector__XXX
   SG_ ControllerTemperatureC : 32|32@1- (1,0) [-40|150] "degC" DRD

BO_ 1731 MPPTAuxiliaryPowerSupplyC: 8 MPPT
   SG_ Aux12VC : 0|32@1- (1,0) [0|20] "V" Vector__XXX
   SG_ Aux3VC : 32|32@1- (1,0) [0|5] "V" Vector__XXX

BO_ 1732 MPPTLimitsC: 8 MPPT
   SG_ MaxOutputVoltageLimitC : 0|32@1- (1,0) [-3.4e+38|3.4e+38] "V" Vector__XXX
   SG_ MaxInputCurrentLimitC : 32|32@1- (1,0) [-3.4e+38|3.4e+38] "A" Vector__XXX

BO_ 1733 MPPTStatusC: 8 MPPT
   SG_ CANRXErrorCounterC : 0|8@1+ (1,0) [0|255] "" Vector__XXX
   SG_ CANTXErrorCounterC : 8|8@1+ (1,0) [0|255] "" Vector__XXX
   SG_ CANTXOverflowCounterC : 16|8@1+ (1,0) [0|255] "" Vector__XXX
   SG_ HWOvervoltageC : 24|1@1+ (1,0) [0|1] "" Vector__XXX
   SG_ HWOvercurrentC : 25|1@1+ (1,0) [0|1] "" Vector__XXX
   SG_ Reserved1C : 26|1@1+ (1,0) [0|1] "" Vector__XXX
   SG_ Undervoltage12VC : 27|1@1+ (1,0) [0|1] "" Vector__XXX
   SG_ BatteryFullC : 28|1@1+ (1,0) [0|1] "" Vector__XXX
   SG_ BatteryLowC : 29|1@1+ (1,0) [0|1] "" Vector__XXX
   SG_ MosfetOverheatC : 30|1@1+ (1,0) [0|1] "" Vector__XXX
   SG_ LowArrayPowerC : 31|1@1+ (1,0) [0|1] "" Vector__XXX
   SG_ GlobalMPPTC : 32|1@1+ (1,0) [0|1] "" Vector__XXX
   SG_ LocalMPPTC : 33|1@1+ (1,0) [0|1] "" Vector__XXX
   SG_ DutyCycleMaxC : 34|1@1+ (1,0) [0|1] "" Vector__XXX
   SG_ DutyCycleMinC : 35|1@1+ (1,0) [0|1] "" Vector__XXX
   SG_ MosfetTempFaultC : 36|1@1+ (1,0) [0|1] "" Vector__XXX
   SG_ OutputVoltageMaxC : 37|1@1+ (1,0) [0|1] "" Vector__XXX
   SG_ InputCurrentMaxC : 38|1@1+ (1,0) [0|1] "" Vector__XXX
   SG_ InputCurrentMinC : 39|1@1+ (1,0) [0|1] "" Vector__XXX
   SG_ ModeC : 40|8@1+ (1,0) [0|1] "" Vector__XXX
   SG_ Reserved2C : 48|8@1+ (1,0) [0|255] "" Vector__XXX
   SG_ TestCounterC : 56|8@1+ (1,0) [0|255] "" Vector__XXX

BO_ 1734 MPPTPowerConnectorC: 8 MPPT
   SG_ OutputVoltageBattSideC : 0|32@1- (1,0) [-3.4e+38|3.4e+38] "V" Vector__XXX
   SG_ ConnectorTemperatureC : 32|32@1- (1,0) [-40|150] "degC" Vector__XXX

BO_ 1736 MPPTModeCommandC: 1 Vector__XXX
   SG_ ModeCmdC : 0|8@1+ (1,0) [0|1] "" Vector__XXX

BO_ 1738 MPPTMaxOutputVoltageCommandC: 4 Vector__XXX
   SG_ MaxOutputVoltageCmdC : 0|32@1- (1,0) [-3.4e+38|3.4e+38] "V" Vector__XXX

BO_ 1739 MPPTMaxOutputCurrentCommandC: 4 Vector__XXX
   SG_ MaxOutputCurrentCmdC : 0|32@1- (1,0) [-3.4e+38|3.4e+38] "A" Vector__XXX

BO_ 1744 MPPTInputMeasurementsD: 8 MPPT
   SG_ InputVoltageD : 0|32@1- (1,0) [-3.4e+38|3.4e+38] "V" Vector__XXX
   SG_ InputCurrentD : 32|32@1- (1,0) [-3.4e+38|3.4e+38] "A" Vector__XXX

BO_ 1745 MPPTOutputMeasurementsD: 8 MPPT
   SG_ OutputVoltageD : 0|32@1- (1,0) [-3.4e+38|3.4e+38] "V" Vector__XXX
   SG_ OutputCurrentD : 32|32@1- (1,0) [-3.4e+38|3.4e+38] "A" Vector__XXX

BO_ 1746 MPPTTemperatureD: 8 MPPT
   SG_ MosfetTemperatureD : 0|32@1- (1,0) [-40|150] "degC" Vector__XXX
   SG_ ControllerTemperatureD : 32|32@1- (1,0) [-40|150] "degC" Vector__XXX

BO_ 1747 MPPTAuxiliaryPowerSupplyD: 8 MPPT
   SG_ Aux12VD : 0|32@1- (1,0) [0|20] "V" Vector__XXX
   SG_ Aux3VD : 32|32@1- (1,0) [0|5] "V" Vector__XXX

BO_ 1748 MPPTLimitsD: 8 MPPT
   SG_ MaxOutputVoltageLimitD : 0|32@1- (1,0) [-3.4e+38|3.4e+38] "V" Vector__XXX
   SG_ MaxInputCurrentLimitD : 32|32@1- (1,0) [-3.4e+38|3.4e+38] "A" Vector__XXX

BO_ 1749 MPPTStatusD: 8 MPPT
   SG_ CANRXErrorCounterD : 0|8@1+ (1,0) [0|255] "" Vector__XXX
   SG_ CANTXErrorCounterD : 8|8@1+ (1,0) [0|255] "" Vector__XXX
   SG_ CANTXOverflowCounterD : 16|8@1+ (1,0) [0|255] "" Vector__XXX
   SG_ HWOvervoltageD : 24|1@1+ (1,0) [0|1] "" Vector__XXX
   SG_ HWOvercurrentD : 25|1@1+ (1,0) [0|1] "" Vector__XXX
   SG_ Reserved1D : 26|1@1+ (1,0) [0|1] "" Vector__XXX
   SG_ Undervoltage12VD : 27|1@1+ (1,0) [0|1] "" Vector__XXX
   SG_ BatteryFullD : 28|1@1+ (1,0) [0|1] "" Vector__XXX
   SG_ BatteryLowD : 29|1@1+ (1,0) [0|1] "" Vector__XXX
   SG_ MosfetOverheatD : 30|1@1+ (1,0) [0|1] "" Vector__XXX
   SG_ LowArrayPowerD : 31|1@1+ (1,0) [0|1] "" Vector__XXX
   SG_ GlobalMPPTD : 32|1@1+ (1,0) [0|1] "" Vector__XXX
   SG_ LocalMPPTD : 33|1@1+ (1,0) [0|1] "" Vector__XXX
   SG_ DutyCycleMaxD : 34|1@1+ (1,0) [0|1] "" Vector__XXX
   SG_ DutyCycleMinD : 35|1@1+ (1,0) [0|1] "" Vector__XXX
   SG_ MosfetTempFaultD : 36|1@1+ (1,0) [0|1] "" Vector__XXX
   SG_ OutputVoltageMaxD : 37|1@1+ (1,0) [0|1] "" Vector__XXX
   SG_ InputCurrentMaxD : 38|1@1+ (1,0) [0|1] "" Vector__XXX
   SG_ InputCurrentMinD : 39|1@1+ (1,0) [0|1] "" Vector__XXX
   SG_ ModeD : 40|8@1+ (1,0) [0|1] "" Vector__XXX
   SG_ Reserved2D : 48|8@1+ (1,0) [0|255] "" Vector__XXX
   SG_ TestCounterD : 56|8@1+ (1,0) [0|255] "" Vector__XXX

BO_ 1750 MPPTPowerConnectorD: 8 MPPT
   SG_ OutputVoltageBattSideD : 0|32@1- (1,0) [-3.4e+38|3.4e+38] "V" Vector__XXX
   SG_ ConnectorTemperatureD : 32|32@1- (1,0) [-40|150] "degC" Vector__XXX

BO_ 1752 MPPTModeCommandD: 1 Vector__XXX
   SG_ ModeCmdD : 0|8@1+ (1,0) [0|1] "" Vector__XXX

BO_ 1754 MPPTMaxOutputVoltageCommandD: 4 Vector__XXX
   SG_ MaxOutputVoltageCmdD : 0|32@1- (1,0) [-3.4e+38|3.4e+38] "V" Vector__XXX

BO_ 1755 MPPTMaxOutputCurrentCommandD: 4 Vector__XXX
   SG_ MaxOutputCurrentCmdD : 0|32@1- (1,0) [-3.4e+38|3.4e+38] "A" Vector__XXX

BO_ 1872 TELTimeSinceBootup: 4 TEL
   SG_ TELTimeSinceBootUp : 0|32@1+ (1,0) [0|4.29497e+09] "s" HVC

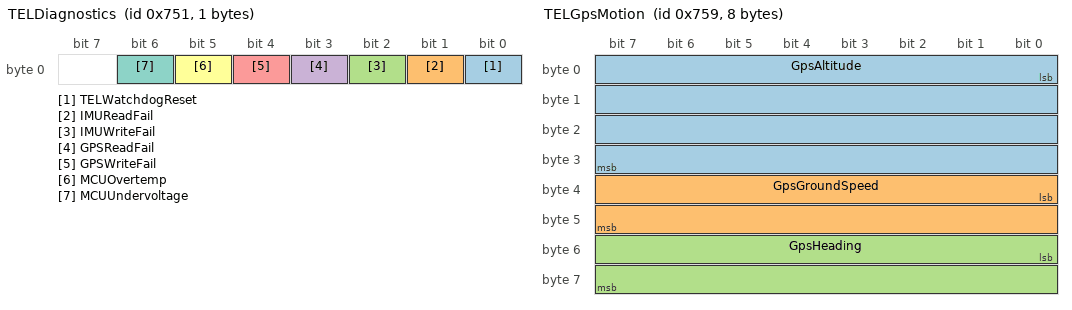
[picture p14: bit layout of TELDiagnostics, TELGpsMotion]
BO_ 1873 TELDiagnostics: 1 TEL
   SG_ TELWatchdogReset : 0|1@1+ (1,0) [0|1] "" Vector__XXX
   SG_ IMUReadFail : 1|1@1+ (1,0) [0|1] "" Vector__XXX
   SG_ IMUWriteFail : 2|1@1+ (1,0) [0|1] "" Vector__XXX
   SG_ GPSReadFail : 3|1@1+ (1,0) [0|1] "" Vector__XXX
   SG_ GPSWriteFail : 4|1@1+ (1,0) [0|1] "" Vector__XXX
   SG_ MCUOvertemp : 5|1@1+ (1,0) [0|1] "" Vector__XXX
   SG_ MCUUndervoltage : 6|1@1+ (1,0) [0|1] "" Vector__XXX

BO_ 1874 TELImuAG_X: 8 TEL
   SG_ ImuAGXAccel : 0|32@1- (1,0) [-3.4e+38|3.4e+38] "m/s^2" Vector__XXX
   SG_ ImuAGXGyro : 32|32@1- (1,0) [-3.4e+38|3.4e+38] "rad/s" Vector__XXX

BO_ 1875 TELImuAGY: 8 TEL
   SG_ ImuAGYAccel : 0|32@1- (1,0) [-3.4e+38|3.4e+38] "m/s^2" Vector__XXX
   SG_ ImuAGYGyro : 32|32@1- (1,0) [-3.4e+38|3.4e+38] "rad/s" Vector__XXX

BO_ 1876 TELImuAGZ: 8 TEL
   SG_ ImuAGZAccel : 0|32@1- (1,0) [-3.4e+38|3.4e+38] "m/s^2" Vector__XXX
   SG_ ImuAGZGyro : 32|32@1- (1,0) [-3.4e+38|3.4e+38] "rad/s" Vector__XXX

BO_ 1877 TELImuMX: 4 TEL
   SG_ ImuMXMag : 0|32@1- (1,0) [-3.4e+38|3.4e+38] "uT" Vector__XXX

BO_ 1878 TELImuMY: 4 TEL
   SG_ ImuMYMag : 0|32@1- (1,0) [-3.4e+38|3.4e+38] "uT" Vector__XXX

BO_ 1879 TELImuMZ: 4 TEL
   SG_ ImuMZMag : 0|32@1- (1,0) [-3.4e+38|3.4e+38] "uT" Vector__XXX

BO_ 1880 TELGpsPosition: 8 TEL
   SG_ GpsLongitude : 0|32@1- (1e-07,0) [-180|180] "deg" Vector__XXX
   SG_ GpsLatitude : 32|32@1- (1e-07,0) [-90|90] "deg" Vector__XXX

BO_ 1881 TELGpsMotion: 8 TEL
   SG_ GpsAltitude : 0|32@1- (0.001,0) [-2.14749e+06|2.14749e+06] "m" Vector__XXX
   SG_ GpsGroundSpeed : 32|16@1+ (0.036,0) [0|2359.27] "km/h" Vector__XXX
   SG_ GpsHeading : 48|16@1+ (0.01,0) [0|360] "deg" Vector__XXX

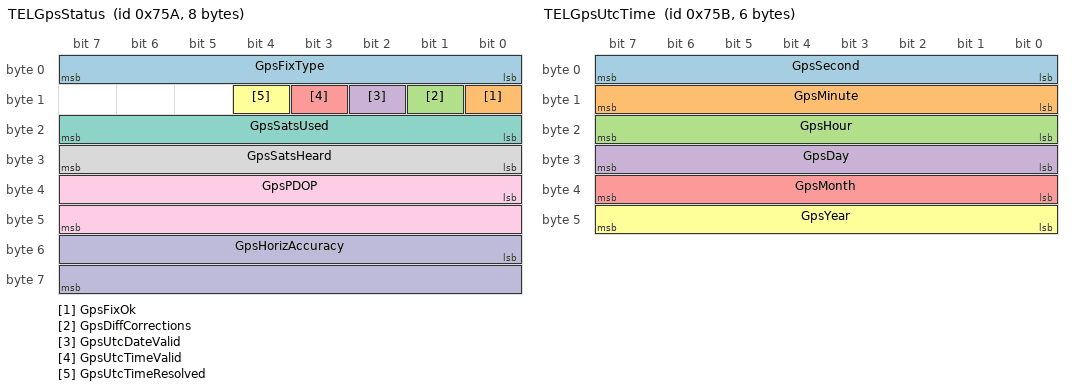
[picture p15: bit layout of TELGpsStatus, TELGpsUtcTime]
BO_ 1882 TELGpsStatus: 8 TEL
   SG_ GpsFixType : 0|8@1+ (1,0) [0|255] "" Vector__XXX
   SG_ GpsFixOk : 8|1@1+ (1,0) [0|1] "" Vector__XXX
   SG_ GpsDiffCorrections : 9|1@1+ (1,0) [0|1] "" Vector__XXX
   SG_ GpsUtcDateValid : 10|1@1+ (1,0) [0|1] "" Vector__XXX
   SG_ GpsUtcTimeValid : 11|1@1+ (1,0) [0|1] "" Vector__XXX
   SG_ GpsUtcTimeResolved : 12|1@1+ (1,0) [0|1] "" Vector__XXX
   SG_ GpsSatsUsed : 16|8@1+ (1,0) [0|255] "" Vector__XXX
   SG_ GpsSatsHeard : 24|8@1+ (1,0) [0|255] "" Vector__XXX
   SG_ GpsPDOP : 32|16@1+ (0.01,0) [0|655.35] "" Vector__XXX
   SG_ GpsHorizAccuracy : 48|16@1+ (0.01,0) [0|655.35] "m" Vector__XXX

BO_ 1883 TELGpsUtcTime: 6 TEL
   SG_ GpsSecond : 0|8@1+ (1,0) [0|60] "s" Vector__XXX
   SG_ GpsMinute : 8|8@1+ (1,0) [0|59] "min" Vector__XXX
   SG_ GpsHour : 16|8@1+ (1,0) [0|23] "h" Vector__XXX
   SG_ GpsDay : 24|8@1+ (1,0) [0.99999|31] "" Vector__XXX
   SG_ GpsMonth : 32|8@1+ (1,0) [0.99999|12] "" Vector__XXX
   SG_ GpsYear : 40|8@1+ (1,2000) [2000|2255] "" Vector__XXX

BO_ 1884 TELCommitHash: 5 TEL
   SG_ TELCommitHash : 7|32@0+ (1,0) [0|4.29497e+09] "" Vector__XXX
   SG_ TELCommitDirty : 32|1@1+ (1,0) [0|1] "" Vector__XXX

BO_ 1891 CANBusLoad: 1 TEL
   SG_ BusLoad : 0|8@1+ (1,0) [0|100] "%" Vector__XXX

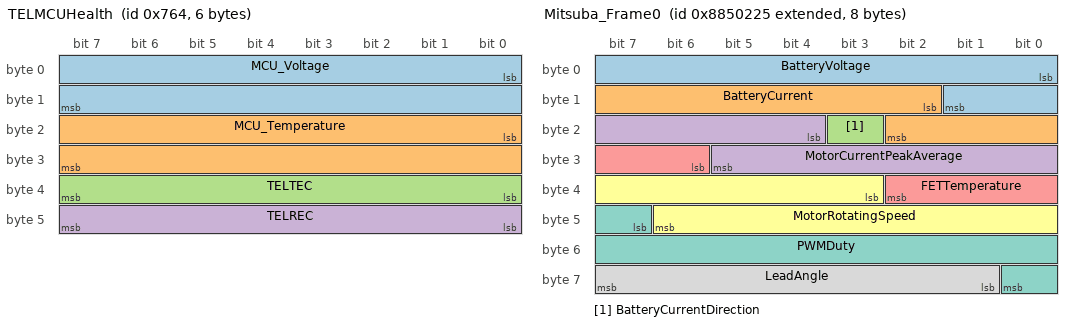
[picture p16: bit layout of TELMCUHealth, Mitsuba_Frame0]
BO_ 1892 TELMCUHealth: 6 TEL
   SG_ MCU_Voltage : 0|16@1+ (1,0) [0|65535] "mV" Vector__XXX
   SG_ MCU_Temperature : 16|16@1- (1,0) [-40|125] "degC" Vector__XXX
   SG_ TELTEC : 32|8@1+ (1,0) [0|255] "" Vector__XXX
   SG_ TELREC : 40|8@1+ (1,0) [0|255] "" Vector__XXX

BO_ 2290418213 Mitsuba_Frame0: 8 MC
   SG_ BatteryVoltage : 0|10@1+ (0.5,0) [0|511.5] "V" DRD
   SG_ BatteryCurrent : 10|9@1+ (1,0) [0|511] "A" DRD
   SG_ BatteryCurrentDirection : 19|1@1+ (1,0) [0|1] "" DRD
   SG_ MotorCurrentPeakAverage : 20|10@1+ (1,0) [0|1023] "A" DRD
   SG_ FETTemperature : 30|5@1+ (5,0) [0|155] "degC" DRD
   SG_ MotorRotatingSpeed : 35|12@1+ (0.106688,0) [0|436.89] "km/h" DRD
   SG_ PWMDuty : 47|10@1+ (0.5,0) [0|511.5] "%" DRD
   SG_ LeadAngle : 57|7@1+ (0.5,0) [0|63.5] "deg" DRD

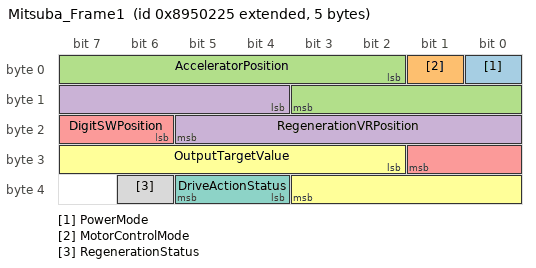
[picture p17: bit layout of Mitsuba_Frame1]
BO_ 2291466789 Mitsuba_Frame1: 5 MC
   SG_ PowerMode : 0|1@1+ (1,0) [0|1] "" Vector__XXX
   SG_ MotorControlMode : 1|1@1+ (1,0) [0|1] "" Vector__XXX
   SG_ AcceleratorPosition : 2|10@1+ (0.5,0) [0|511.5] "%" Vector__XXX
   SG_ RegenerationVRPosition : 12|10@1+ (0.5,0) [0|511.5] "%" Vector__XXX
   SG_ DigitSWPosition : 22|4@1+ (1,0) [0|15] "" Vector__XXX
   SG_ OutputTargetValue : 26|10@1+ (0.5,0) [0|511.5] "A" Vector__XXX
   SG_ DriveActionStatus : 36|2@1+ (1,0) [0|3] "" Vector__XXX
   SG_ RegenerationStatus : 38|1@1+ (1,0) [0|1] "" Vector__XXX

BO_ 2292515365 Mitsuba_Frame2: 5 MC
   SG_ AnalogSensorError : 0|1@1+ (1,0) [0|1] "" DRD
   SG_ MotorCurrentSensorUError : 1|1@1+ (1,0) [0|1] "" DRD
   SG_ MotorCurrentSensorWError : 2|1@1+ (1,0) [0|1] "" DRD
   SG_ FETThermistorError : 3|1@1+ (1,0) [0|1] "" DRD
   SG_ RFU : 4|1@1+ (1,0) [0|1] "" DRD
   SG_ BatteryVoltageSensorError : 5|1@1+ (1,0) [0|1] "" DRD
   SG_ BatteryCurrentSensorError : 6|1@1+ (1,0) [0|1] "" DRD
   SG_ BatteryCurrentSensorAdjustError : 7|1@1+ (1,0) [0|1] "" DRD
   SG_ MotorCurrentSensorAdjustError : 8|1@1+ (1,0) [0|1] "" DRD
   SG_ AcceleratorPositionError : 9|1@1+ (1,0) [0|1] "" DRD
   SG_ RFU2 : 10|1@1+ (1,0) [0|1] "" DRD
   SG_ ControllerVoltageSensorError : 11|1@1+ (1,0) [0|1] "" DRD
   SG_ RFU3 : 12|4@1+ (1,0) [0|15] "" DRD
   SG_ PowerSystemError : 16|1@1+ (1,0) [0|1] "" DRD
   SG_ OverCurrentError : 17|1@1+ (1,0) [0|1] "" DRD
   SG_ RFU4 : 18|1@1+ (1,0) [0|1] "" DRD
   SG_ OverVoltageError : 19|1@1+ (1,0) [0|1] "" DRD
   SG_ RFU5 : 20|1@1+ (1,0) [0|1] "" DRD
   SG_ OverCurrentLimit : 21|1@1+ (1,0) [0|1] "" DRD
   SG_ RFU6 : 22|2@1+ (1,0) [0|3] "" DRD
   SG_ MotorSystemError : 24|1@1+ (1,0) [0|1] "" DRD
   SG_ MotorLock : 25|1@1+ (1,0) [0|1] "" DRD
   SG_ HallSensorShort : 26|1@1+ (1,0) [0|1] "" DRD
   SG_ HallSensorOpen : 27|1@1+ (1,0) [0|1] "" DRD
   SG_ RFU7 : 28|4@1+ (1,0) [0|15] "" DRD
   SG_ OverHeatLevel : 32|2@1+ (1,0) [0|3] "" DRD

BO_ 2297992512 MitsubaDataRequest: 1 DRD
   SG_ RequestForFrames : 0|3@1+ (1,0) [0|7] "" Vector__XXX

BO_ 2566869221 OBCStatus: 8 OBC
   SG_ OutputVoltage : 0|16@1+ (0.1,0) [0|6553.5] "V" Vector__XXX
   SG_ OutputCurrent : 16|16@1+ (0.1,0) [0|6553.5] "A" Vector__XXX
   SG_ HardwareProtection : 32|1@1+ (1,0) [0|1] "" Vector__XXX
   SG_ TemperatureProtection : 33|1@1+ (1,0) [0|1] "" Vector__XXX
   SG_ InputVoltageStatus : 34|2@1+ (1,0) [0|3] "" Vector__XXX
   SG_ OutputUnderVoltage : 36|1@1+ (1,0) [0|1] "" Vector__XXX
   SG_ OutputOverVoltage : 37|1@1+ (1,0) [0|1] "" Vector__XXX
   SG_ OutputOverCurrent : 38|1@1+ (1,0) [0|1] "" Vector__XXX
   SG_ OutputShortCircuit : 39|1@1+ (1,0) [0|1] "" Vector__XXX
   SG_ CommunicationStatus : 40|1@1+ (1,0) [0|1] "" Vector__XXX
   SG_ WorkingStatus : 41|2@1+ (1,0) [0|3] "" Vector__XXX
   SG_ CompletionOfInitialization : 43|1@1+ (1,0) [0|1] "" Vector__XXX
   SG_ FanEnable : 44|1@1+ (1,0) [0|1] "" Vector__XXX
   SG_ CoolingPumpFanEnable : 45|1@1+ (1,0) [0|1] "" Vector__XXX
   SG_ CCsignalStatus : 48|2@1+ (1,0) [0|3] "" Vector__XXX
   SG_ CPSignalStatus : 50|1@1+ (1,0) [0|1] "" Vector__XXX
   SG_ ChargingSocketTempFault : 51|1@1+ (1,0) [0|1] "" Vector__XXX
   SG_ ElectronicLockState : 52|3@1+ (1,0) [0|4] "" Vector__XXX
   SG_ S2SwitchControlStatus : 55|1@1+ (1,0) [0|1] "" Vector__XXX
   SG_ Temperature : 56|8@1+ (1,-40) [-40|215] "degC" Vector__XXX

CM_ BU_ HVC "High voltage controller (precharge, pack shunt current, HV faults)";
CM_ BU_ MST "Cascadia BMS master board";
CM_ BU_ DIST "Low voltage power distribution board";
CM_ BU_ TEL "Telemetry board (IMU, GPS)";
CM_ BU_ MDI "Motor drive interface board (DAC throttle/regen to the Mitsuba controller)";
CM_ BU_ STR "Steering wheel board";
CM_ BU_ DRD "Driver display / dashboard board";
CM_ BU_ MPPT "Maximum power point trackers A-D";
CM_ BU_ MC "Mitsuba motor controller";
CM_ BU_ MEMORATOR "Kvaser Memorator CAN logger";
CM_ BU_ OBC "On-board charger";
CM_ BO_ 512 "MST heartbeat and pack status. Bit order per mst/app/can_messages.c (after MST PR 111).";
CM_ SG_ 512 NumCommFails "Total isoSPI comm failures, saturates at 65535";
CM_ BO_ 513 "Pack voltage summary. Min/Max module indices are 1-based (Mod0 here is index 1).";
CM_ BO_ 514 "Temperature summary. Min/Max indices are 1-based. Firmware bug: AvgTemp high byte is always 0, so negative temperatures read as 256 + T.";
CM_ BO_ 515 "Bit n set = module n balancing (0-based, same numbering as ModN signals)";
CM_ BO_ 544 "Firmware bug: high byte of each temperature is always 0, so negative temperatures read as 256 + T.";
CM_ BO_ 545 "Firmware bug: high byte of each temperature is always 0, so negative temperatures read as 256 + T.";
CM_ BO_ 546 "Firmware bug: high byte of each temperature is always 0, so negative temperatures read as 256 + T.";
CM_ BO_ 547 "Firmware bug: high byte of each temperature is always 0, so negative temperatures read as 256 + T.";
CM_ BO_ 548 "Firmware bug: high byte of each temperature is always 0, so negative temperatures read as 256 + T.";
CM_ BO_ 549 "Firmware bug: high byte of each temperature is always 0, so negative temperatures read as 256 + T.";
CM_ BO_ 550 "Firmware bug: high byte of each temperature is always 0, so negative temperatures read as 256 + T.";
CM_ BO_ 551 "Firmware bug: high byte of each temperature is always 0, so negative temperatures read as 256 + T.";
CM_ BO_ 560 "Per-module warnings (bits 0-2) and faults (bits 4-7) for Mod0-Mod7";
CM_ BO_ 561 "Per-module warnings (bits 0-2) and faults (bits 4-7) for Mod8-Mod15";
CM_ BO_ 562 "Per-module warnings (bits 0-2) and faults (bits 4-7) for Mod16-Mod23";
CM_ BO_ 563 "Per-module warnings (bits 0-2) and faults (bits 4-7) for Mod24-Mod31";
CM_ BO_ 768 "Logger RTC timestamp. TEL uses it once as a fallback until GPS time is valid.";
CM_ BO_ 800 "INA228 HV pack current, big-endian";
CM_ BO_ 801 "One bit per HVC fault flag (FaultFlags in hvc_types.h). Flags latch until HVC reset. DIST treats any non-zero byte as an external fault";
CM_ SG_ 801 MasterboardFault "Firmware: mst_fault (MST fault pin)";
CM_ SG_ 801 MstUnhealthyFault "Firmware: mst_unhealthy (MST heartbeat reports a fault)";
CM_ SG_ 801 UndercurrentFault "Firmware: reverse_current";
CM_ SG_ 801 DcdcThermistorFault "Firmware: dcdc_overtemp";
CM_ BO_ 802 "Heartbeat. uint32 counter, big-endian, +1 per send.";
CM_ BO_ 803 "Resent every 500 ms in LV_POWERUP until DIST acks (0x3A2); DIST starts on bit 0";
CM_ BO_ 805 "LV current sensor, big-endian";
CM_ BO_ 806 "DC-DC thermistor temperature, big-endian";
CM_ SG_ 806 DcdcTemperature "Firmware sends milli-degC";
CM_ BO_ 928 "32-bit big-endian counter (DIST PR 78)";
CM_ BO_ 929 "Sent every 200 ms in all states. All zero until DIST enters FAULT, then holds the causes latched on FAULT entry until reset.";
CM_ BO_ 931 "Each step is 5 mA; saturates at 1275 mA";
CM_ BO_ 932 "Firmware branch ID";
CM_ BO_ 1025 "Motor command to MDI. Also sent immediately when the brake is pressed.";
CM_ SG_ 1027 SOC "SOC_MAX is 1.04 so values up to 104 are possible";
CM_ SG_ 1281 MDIMotorOverTemp "Set at 100 degC, cleared at 95 degC";
CM_ SG_ 1281 MDIVoltageOverThreshold "Not set by current MDI firmware (always 0)";
CM_ SG_ 1281 MDIRTDFault "1 = RTD fault latched: +1 per faulted read, -1 per clean read, sets at 5, clears at 0";
CM_ SG_ 1281 MDIRTDCommError "1 = SPI error, or MAX31865 missing/reset";
CM_ SG_ 1281 MDITEC "CAN transmit error counter (TEC) read from the CAN peripheral. +8 per failed transmit, -1 per successful one. 0 = healthy, >127 = error passive, >255 = bus-off. A lone node with no ACK sits at 128.";
CM_ SG_ 1281 MDIREC "CAN receive error counter (REC) read from the CAN peripheral. +1 per receive error, -1 per good frame. 0 = healthy, >127 = error passive.";
CM_ SG_ 1282 RTDReadSuccess "1 = valid read, 0 = fault/HAL error";
CM_ SG_ 1282 RTDFaultFlags "MAX31865 fault register: 0x80 = RTD high, 0x40 = RTD low, 0x04 = OV/UV, 0 = none";
CM_ SG_ 1026 DRDMCUSupplyVoltage "0 = read failed";
CM_ SG_ 1026 DRDTEC "CAN transmit error counter (TEC) read from the CAN peripheral. +8 per failed transmit, -1 per successful one. 0 = healthy, >127 = error passive, >255 = bus-off. A lone node with no ACK sits at 128.";
CM_ SG_ 1026 DRDREC "CAN receive error counter (REC) read from the CAN peripheral. +1 per receive error, -1 per good frame. 0 = healthy, >127 = error passive.";
CM_ SG_ 1027 DRDMCUOverTemp "1 = fault: DRD MCU over temperature";
CM_ SG_ 1027 DRDMCUUnderVoltage "1 = fault: DRD MCU under voltage";
CM_ SG_ 1425 STRMCUVoltage "0 = read failed";
CM_ SG_ 1425 STRTEC "CAN transmit error counter (TEC) read from the CAN peripheral. +8 per failed transmit, -1 per successful one. 0 = healthy, >127 = error passive, >255 = bus-off. A lone node with no ACK sits at 128.";
CM_ SG_ 1425 STRREC "CAN receive error counter (REC) read from the CAN peripheral. +1 per receive error, -1 per good frame. 0 = healthy, >127 = error passive.";
CM_ SG_ 1426 STRMCUUnderVoltage "1 = fault: STR MCU Vdd below 2400 mV";
CM_ SG_ 1426 STRMCUOverTemp "1 = fault: STR MCU above 105 degC";
CM_ BO_ 1408 "Steering inputs. Firmware sends 8 bytes; bytes 4-7 are 0.";
CM_ BO_ 1410 "Not sent by current STR firmware (kept for existing dashboards)";
CM_ BO_ 1704 "Command to MPPT A";
CM_ BO_ 1706 "Command to MPPT A";
CM_ BO_ 1707 "Command to MPPT A";
CM_ BO_ 1720 "Command to MPPT B";
CM_ BO_ 1722 "Command to MPPT B";
CM_ BO_ 1723 "Command to MPPT B";
CM_ BO_ 1736 "Command to MPPT C";
CM_ BO_ 1738 "Command to MPPT C";
CM_ BO_ 1739 "Command to MPPT C";
CM_ BO_ 1752 "Command to MPPT D";
CM_ BO_ 1754 "Command to MPPT D";
CM_ BO_ 1755 "Command to MPPT D";
CM_ BO_ 1872 "HVC uses this as the TEL heartbeat";
CM_ BO_ 1880 "Only sent with a valid fix";
CM_ BO_ 1881 "Only sent with a valid fix";
CM_ BO_ 1883 "Only sent with a valid UTC date and time";
CM_ BO_ 1892 "TEL MCU health: Vdd and die temperature, 10 Hz (firmware tel/app/diagnostics.c)";
CM_ BO_ 2290418213 "Sent in response to MitsubaDataRequest";
CM_ SG_ 2290418213 MotorRotatingSpeed "rpm x 0.106688 (0.283 m wheel radius). Raw value is rpm.";
CM_ SG_ 2290418213 PWMDuty "Only valid in PWM control mode";
CM_ SG_ 2290418213 LeadAngle "Electrical lead angle";
CM_ BO_ 2291466789 "Sent in response to MitsubaDataRequest";
CM_ SG_ 2291466789 OutputTargetValue "Target current (current mode)";
CM_ BO_ 2292515365 "Sent in response to MitsubaDataRequest";
CM_ SG_ 2292515365 AnalogSensorError "AD sensor error";
CM_ SG_ 2292515365 MotorCurrentSensorUError "U phase current sensor error";
CM_ SG_ 2292515365 MotorCurrentSensorWError "W phase current sensor error";
CM_ SG_ 2292515365 FETThermistorError "Controller temperature sensor error";
CM_ SG_ 2292515365 BatteryCurrentSensorError "Battery current sensor zero (reference) position error";
CM_ SG_ 2292515365 MotorCurrentSensorAdjustError "Motor current sensor zero (reference) position error";
CM_ SG_ 2292515365 ControllerVoltageSensorError "12V line voltage sensor error";
CM_ SG_ 2292515365 PowerSystemError "Power line error";
CM_ SG_ 2292515365 MotorLock "Motor locked and not rotating";
CM_ BO_ 2297992512 "Sent by DRD every ~100 ms";
CM_ BO_ 516 "First 4 bytes of the git commit SHA the MST firmware was built from (0 = unknown). Dirty = built with uncommitted changes.";
CM_ BO_ 810 "First 4 bytes of the git commit SHA the HVC firmware was built from (0 = unknown). Dirty = built with uncommitted changes.";
CM_ BO_ 933 "First 4 bytes of the git commit SHA the DIST firmware was built from (0 = unknown). Dirty = built with uncommitted changes.";
CM_ BO_ 1029 "First 4 bytes of the git commit SHA the DRD firmware was built from (0 = unknown). Dirty = built with uncommitted changes.";
CM_ BO_ 1284 "First 4 bytes of the git commit SHA the MDI firmware was built from (0 = unknown). Dirty = built with uncommitted changes.";
CM_ BO_ 1411 "First 4 bytes of the git commit SHA the STR firmware was built from (0 = unknown). Dirty = built with uncommitted changes.";
CM_ BO_ 1884 "First 4 bytes of the git commit SHA the TEL firmware was built from (0 = unknown). Dirty = built with uncommitted changes.";
CM_ SG_ 2297992512 RequestForFrames "Bitmask of frames requested: bit0 Frame0, bit1 Frame1, bit2 Frame2 (0b111 = all frames)";
CM_ SG_ 2566869221 CCsignalStatus "CC resistance in charger gun: 1.5k ohm = 8A max, 680 ohm = 16A, 220 ohm = 32A";
CM_ SG_ 2566869221 CPSignalStatus "CP duty cycle indicates supply capacity";
CM_ SG_ 2566869221 ChargingSocketTempFault "Overheating when temp > 90 degC for > 15 min, or temp > 120 degC";
CM_ SG_ 1892 TELTEC "CAN transmit error counter (TEC) read from the CAN peripheral. +8 per failed transmit, -1 per successful one. 0 = healthy, >127 = error passive, >255 = bus-off. A lone node with no ACK sits at 128.";
CM_ SG_ 1892 TELREC "CAN receive error counter (REC) read from the CAN peripheral. +1 per receive error, -1 per good frame. 0 = healthy, >127 = error passive.";
BA_DEF_ "BusType" STRING ;
BA_DEF_ BO_ "VFrameFormat" ENUM "StandardCAN","ExtendedCAN","reserved","J1939PG";
BA_DEF_ BO_ "GenMsgCycleTime" INT 0 65535;
BA_DEF_ BO_ "GenMsgBackgroundColor" STRING ;
BA_DEF_ BO_ "GenMsgForegroundColor" STRING ;
BA_DEF_DEF_ "BusType" "CAN";
BA_DEF_DEF_ "VFrameFormat" "StandardCAN";
BA_DEF_DEF_ "GenMsgCycleTime" 0;
BA_DEF_DEF_ "GenMsgBackgroundColor" "#ffffff";
BA_DEF_DEF_ "GenMsgForegroundColor" "#000000";
BA_ "GenMsgCycleTime" BO_ 512 1000;
BA_ "GenMsgCycleTime" BO_ 800 200;
BA_ "GenMsgCycleTime" BO_ 801 200;
BA_ "GenMsgCycleTime" BO_ 802 1000;
BA_ "GenMsgCycleTime" BO_ 804 200;
BA_ "GenMsgCycleTime" BO_ 805 200;
BA_ "GenMsgCycleTime" BO_ 806 200;
BA_ "GenMsgCycleTime" BO_ 807 200;
BA_ "GenMsgCycleTime" BO_ 808 200;
BA_ "GenMsgCycleTime" BO_ 809 200;
BA_ "GenMsgCycleTime" BO_ 928 500;
BA_ "GenMsgCycleTime" BO_ 930 500;
BA_ "GenMsgCycleTime" BO_ 931 1000;
BA_ "GenMsgCycleTime" BO_ 932 1000;
BA_ "GenMsgCycleTime" BO_ 1025 25;
BA_ "GenMsgCycleTime" BO_ 1026 1000;
BA_ "GenMsgCycleTime" BO_ 1027 100;
BA_ "GenMsgCycleTime" BO_ 1028 1000;
BA_ "GenMsgCycleTime" BO_ 1280 1000;
BA_ "GenMsgCycleTime" BO_ 1281 1000;
BA_ "GenMsgCycleTime" BO_ 1282 1000;
BA_ "GenMsgCycleTime" BO_ 1408 100;
BA_ "GenMsgCycleTime" BO_ 1409 1000;
BA_ "GenMsgCycleTime" BO_ 1425 100;
BA_ "GenMsgCycleTime" BO_ 1426 100;
BA_ "GenMsgCycleTime" BO_ 1872 1000;
BA_ "GenMsgCycleTime" BO_ 1873 100;
BA_ "GenMsgCycleTime" BO_ 1874 100;
BA_ "GenMsgCycleTime" BO_ 1875 100;
BA_ "GenMsgCycleTime" BO_ 1876 100;
BA_ "GenMsgCycleTime" BO_ 1877 100;
BA_ "GenMsgCycleTime" BO_ 1878 100;
BA_ "GenMsgCycleTime" BO_ 1879 100;
BA_ "GenMsgCycleTime" BO_ 1880 1000;
BA_ "GenMsgCycleTime" BO_ 1881 1000;
BA_ "GenMsgCycleTime" BO_ 1882 1000;
BA_ "GenMsgCycleTime" BO_ 1883 1000;
BA_ "GenMsgCycleTime" BO_ 1891 100;
BA_ "GenMsgCycleTime" BO_ 1892 100;
BA_ "VFrameFormat" BO_ 2290418213 1;
BA_ "GenMsgCycleTime" BO_ 2290418213 100;
BA_ "VFrameFormat" BO_ 2291466789 1;
BA_ "GenMsgCycleTime" BO_ 2291466789 100;
BA_ "VFrameFormat" BO_ 2292515365 1;
BA_ "GenMsgCycleTime" BO_ 2292515365 100;
BA_ "VFrameFormat" BO_ 2297992512 1;
BA_ "GenMsgCycleTime" BO_ 2297992512 100;
BA_ "VFrameFormat" BO_ 2566869221 1;
VAL_ 804 HVCState 14 "UNKNOWN" 13 "FAULT" 12 "MONITORING" 11 "LV_POWERUP" 10 "CLOSE_HLIM" 9 "CLOSE_LLIM" 8 "MPPT_PRECHARGE" 7 "MOTOR_PRECHARGE" 6 "OPEN_DISCHARGE_RELAY" 5 "HV_CONNECT" 4 "FANS_POWERUP" 3 "MST_STATUS_CHECK" 2 "MST_HANDSHAKE" 1 "TEL_STARTUP" 0 "RESET";
VAL_ 1025 Direction 1 "Forward" 0 "Reverse";
VAL_ 1025 EcoModeOn 1 "Eco" 0 "Power";
VAL_ 1025 SpeedUnits 1 "KPH" 0 "MPH";
VAL_ 1027 DriveState 4 "REVERSE" 3 "PARK" 2 "CRUISE" 1 "FORWARD" 0 "INVALID";
VAL_ 1282 RTDFaultFlags 128 "RTD high" 64 "RTD low" 4 "OV/UV" 0 "None";
VAL_ 1882 GpsFixType 5 "TimeOnly" 4 "GnssDeadReckoning" 3 "Fix3D" 2 "Fix2D" 1 "DeadReckoning" 0 "NoFix";
VAL_ 2290418213 BatteryCurrentDirection 1 "Negative" 0 "Positive";
VAL_ 2291466789 PowerMode 1 "Power" 0 "Eco";
VAL_ 2291466789 MotorControlMode 1 "PWM" 0 "Current";
VAL_ 2291466789 DriveActionStatus 3 "Reverse" 2 "Forward" 1 "RFU" 0 "Stop";
VAL_ 2291466789 RegenerationStatus 1 "Regeneration" 0 "Drive";
VAL_ 2566869221 HardwareProtection 1 "HardwareProtection" 0 "Normal";
VAL_ 2566869221 TemperatureProtection 1 "InternalTempProtection" 0 "Normal";
VAL_ 2566869221 InputVoltageStatus 3 "NoInputVoltage" 2 "InputOverVoltage" 1 "InputUnderVoltage" 0 "Normal";
VAL_ 2566869221 OutputUnderVoltage 1 "Fault" 0 "Normal";
VAL_ 2566869221 OutputOverVoltage 1 "Fault" 0 "Normal";
VAL_ 2566869221 OutputOverCurrent 1 "Fault" 0 "Normal";
VAL_ 2566869221 OutputShortCircuit 1 "Fault" 0 "Normal";
VAL_ 2566869221 CommunicationStatus 1 "ReceiveTimeout" 0 "Normal";
VAL_ 2566869221 WorkingStatus 3 "StopOrStandby" 2 "Stopped" 1 "Working" 0 "Undefined";
VAL_ 2566869221 CompletionOfInitialization 1 "Complete" 0 "NotComplete";
VAL_ 2566869221 FanEnable 1 "On" 0 "Off";
VAL_ 2566869221 CoolingPumpFanEnable 1 "On" 0 "Off";
VAL_ 2566869221 CCsignalStatus 3 "ResistanceDetectionError" 2 "NormallyConnected" 1 "HalfConnected" 0 "NotConnected";
VAL_ 2566869221 CPSignalStatus 1 "CPSignalNormal" 0 "NoCPSignal";
VAL_ 2566869221 ChargingSocketTempFault 1 "Overheating" 0 "Normal";
VAL_ 2566869221 ElectronicLockState 4 "LockedFault" 3 "UnlockFault" 2 "Unlocked" 1 "Locked" 0 "InJudgment";
VAL_ 2566869221 S2SwitchControlStatus 1 "Closed" 0 "SwitchOff";
SIG_VALTYPE_ 1696 InputVoltageA : 1;
SIG_VALTYPE_ 1696 InputCurrentA : 1;
SIG_VALTYPE_ 1697 OutputVoltageA : 1;
SIG_VALTYPE_ 1697 OutputCurrentA : 1;
SIG_VALTYPE_ 1698 MosfetTemperatureA : 1;
SIG_VALTYPE_ 1698 ControllerTemperatureA : 1;
SIG_VALTYPE_ 1699 Aux12VA : 1;
SIG_VALTYPE_ 1699 Aux3VA : 1;
SIG_VALTYPE_ 1700 MaxOutputVoltageLimitA : 1;
SIG_VALTYPE_ 1700 MaxInputCurrentLimitA : 1;
SIG_VALTYPE_ 1702 OutputVoltageBattSideA : 1;
SIG_VALTYPE_ 1702 ConnectorTemperatureA : 1;
SIG_VALTYPE_ 1706 MaxOutputVoltageCmdA : 1;
SIG_VALTYPE_ 1707 MaxOutputCurrentCmdA : 1;
SIG_VALTYPE_ 1712 InputVoltageB : 1;
SIG_VALTYPE_ 1712 InputCurrentB : 1;
SIG_VALTYPE_ 1713 OutputVoltageB : 1;
SIG_VALTYPE_ 1713 OutputCurrentB : 1;
SIG_VALTYPE_ 1714 MosfetTemperatureB : 1;
SIG_VALTYPE_ 1714 ControllerTemperatureB : 1;
SIG_VALTYPE_ 1715 Aux12VB : 1;
SIG_VALTYPE_ 1715 Aux3VB : 1;
SIG_VALTYPE_ 1716 MaxOutputVoltageLimitB : 1;
SIG_VALTYPE_ 1716 MaxInputCurrentLimitB : 1;
SIG_VALTYPE_ 1718 OutputVoltageBattSideB : 1;
SIG_VALTYPE_ 1718 ConnectorTemperatureB : 1;
SIG_VALTYPE_ 1722 MaxOutputVoltageCmdB : 1;
SIG_VALTYPE_ 1723 MaxOutputCurrentCmdB : 1;
SIG_VALTYPE_ 1728 InputVoltageC : 1;
SIG_VALTYPE_ 1728 InputCurrentC : 1;
SIG_VALTYPE_ 1729 OutputVoltageC : 1;
SIG_VALTYPE_ 1729 OutputCurrentC : 1;
SIG_VALTYPE_ 1730 MosfetTemperatureC : 1;
SIG_VALTYPE_ 1730 ControllerTemperatureC : 1;
SIG_VALTYPE_ 1731 Aux12VC : 1;
SIG_VALTYPE_ 1731 Aux3VC : 1;
SIG_VALTYPE_ 1732 MaxOutputVoltageLimitC : 1;
SIG_VALTYPE_ 1732 MaxInputCurrentLimitC : 1;
SIG_VALTYPE_ 1734 OutputVoltageBattSideC : 1;
SIG_VALTYPE_ 1734 ConnectorTemperatureC : 1;
SIG_VALTYPE_ 1738 MaxOutputVoltageCmdC : 1;
SIG_VALTYPE_ 1739 MaxOutputCurrentCmdC : 1;
SIG_VALTYPE_ 1744 InputVoltageD : 1;
SIG_VALTYPE_ 1744 InputCurrentD : 1;
SIG_VALTYPE_ 1745 OutputVoltageD : 1;
SIG_VALTYPE_ 1745 OutputCurrentD : 1;
SIG_VALTYPE_ 1746 MosfetTemperatureD : 1;
SIG_VALTYPE_ 1746 ControllerTemperatureD : 1;
SIG_VALTYPE_ 1747 Aux12VD : 1;
SIG_VALTYPE_ 1747 Aux3VD : 1;
SIG_VALTYPE_ 1748 MaxOutputVoltageLimitD : 1;
SIG_VALTYPE_ 1748 MaxInputCurrentLimitD : 1;
SIG_VALTYPE_ 1750 OutputVoltageBattSideD : 1;
SIG_VALTYPE_ 1750 ConnectorTemperatureD : 1;
SIG_VALTYPE_ 1754 MaxOutputVoltageCmdD : 1;
SIG_VALTYPE_ 1755 MaxOutputCurrentCmdD : 1;
SIG_VALTYPE_ 1874 ImuAGXAccel : 1;
SIG_VALTYPE_ 1874 ImuAGXGyro : 1;
SIG_VALTYPE_ 1875 ImuAGYAccel : 1;
SIG_VALTYPE_ 1875 ImuAGYGyro : 1;
SIG_VALTYPE_ 1876 ImuAGZAccel : 1;
SIG_VALTYPE_ 1876 ImuAGZGyro : 1;
SIG_VALTYPE_ 1877 ImuMXMag : 1;
SIG_VALTYPE_ 1878 ImuMYMag : 1;
SIG_VALTYPE_ 1879 ImuMZMag : 1;
